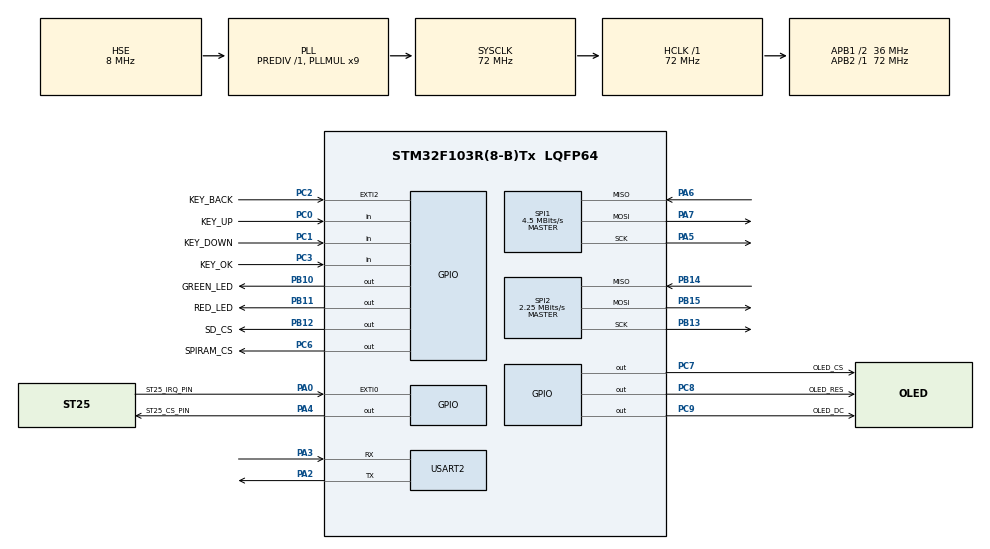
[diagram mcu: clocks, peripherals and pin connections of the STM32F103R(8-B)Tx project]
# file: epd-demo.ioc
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FATFS._CODE_PAGE=1252
FATFS._MAX_SS=512
FATFS._MIN_SS=512
FATFS._USE_LFN=1
Mcu.Family=STM32F1
Mcu.Name=STM32F103R(8-B)Tx
Mcu.Package=LQFP64
NVIC.EXTI0_IRQn=true\:0\:0\:false\:false\:true\:true\:true
NVIC.EXTI2_IRQn=true\:1\:0\:true\:false\:true\:true\:true
NVIC.PriorityGroup=NVIC_PRIORITYGROUP_4
NVIC.TIM3_IRQn=true\:0\:0\:false\:false\:true\:true\:true
PA0-WKUP.GPIO_Label=ST25_IRQ_PIN
PA0-WKUP.Signal=GPXTI0
PA13.Mode=Serial_Wire
PA13.Signal=SYS_JTMS-SWDIO
PA14.Mode=Serial_Wire
PA14.Signal=SYS_JTCK-SWCLK
PA2.Mode=Asynchronous
PA2.Signal=USART2_TX
PA3.Mode=Asynchronous
PA3.Signal=USART2_RX
PA4.GPIO_Label=ST25_CS_PIN
PA4.GPIO_PuPd=GPIO_PULLUP
PA4.GPIO_Speed=GPIO_SPEED_FREQ_HIGH
PA4.Signal=GPIO_Output
PA5.Mode=Full_Duplex_Master
PA5.Signal=SPI1_SCK
PA6.Mode=Full_Duplex_Master
PA6.Signal=SPI1_MISO
PA7.Mode=Full_Duplex_Master
PA7.Signal=SPI1_MOSI
PB10.GPIO_Label=GREEN_LED
PB10.GPIO_PuPd=GPIO_PULLDOWN
PB10.PinState=GPIO_PIN_RESET
PB10.Signal=GPIO_Output
PB11.GPIO_Label=RED_LED
PB11.GPIO_PuPd=GPIO_PULLDOWN
PB11.Signal=GPIO_Output
PB12.GPIO_Label=SD_CS
PB12.GPIO_PuPd=GPIO_PULLUP
PB12.GPIO_Speed=GPIO_SPEED_FREQ_HIGH
PB12.PinState=GPIO_PIN_SET
PB12.Signal=GPIO_Output
PB13.Mode=Full_Duplex_Master
PB13.Signal=SPI2_SCK
PB14.Mode=Full_Duplex_Master
PB14.Signal=SPI2_MISO
PB15.Mode=Full_Duplex_Master
PB15.Signal=SPI2_MOSI
PC0.GPIO_Label=KEY_UP
PC0.GPIO_PuPd=GPIO_PULLUP
PC0.Signal=GPIO_Input
PC1.GPIO_Label=KEY_DOWN
PC1.GPIO_PuPd=GPIO_PULLUP
PC1.Signal=GPIO_Input
PC2.GPIO_Label=KEY_BACK
PC2.GPIO_ModeDefaultEXTI=GPIO_MODE_IT_FALLING
PC2.GPIO_PuPd=GPIO_PULLUP
PC2.Signal=GPXTI2
PC3.GPIO_Label=KEY_OK
PC3.GPIO_PuPd=GPIO_PULLUP
PC3.Signal=GPIO_Input
PC6.GPIO_Label=SPIRAM_CS
PC6.GPIO_PuPd=GPIO_PULLUP
PC6.GPIO_Speed=GPIO_SPEED_FREQ_HIGH
PC6.PinState=GPIO_PIN_SET
PC6.Signal=GPIO_Output
PC7.GPIO_Label=OLED_CS
PC7.GPIO_PuPd=GPIO_PULLUP
PC7.GPIO_Speed=GPIO_SPEED_FREQ_HIGH
PC7.PinState=GPIO_PIN_SET
PC7.Signal=GPIO_Output
PC8.GPIO_Label=OLED_RES
PC8.GPIO_PuPd=GPIO_PULLUP
PC8.GPIO_Speed=GPIO_SPEED_FREQ_LOW
PC8.PinState=GPIO_PIN_RESET
PC8.Signal=GPIO_Output
PC9.GPIO_Label=OLED_DC
PC9.GPIO_Speed=GPIO_SPEED_FREQ_HIGH
PC9.PinState=GPIO_PIN_RESET
PC9.Signal=GPIO_Output
PD0-OSC_IN.Mode=HSE-External-Oscillator
PD0-OSC_IN.Signal=RCC_OSC_IN
PD1-OSC_OUT.Mode=HSE-External-Oscillator
PD1-OSC_OUT.Signal=RCC_OSC_OUT
ProjectManager.HeapSize=0x400
ProjectManager.StackSize=0x800
ProjectManager.TargetToolchain=MDK-ARM V5
RCC.AHBFreq_Value=72000000
RCC.APB1CLKDivider=RCC_HCLK_DIV2
RCC.APB1Freq_Value=36000000
RCC.APB1TimFreq_Value=72000000
RCC.APB2Freq_Value=72000000
RCC.APB2TimFreq_Value=72000000
RCC.HCLKFreq_Value=72000000
RCC.PLLMUL=RCC_PLL_MUL9
RCC.PLLSourceVirtual=RCC_PLLSOURCE_HSE
RCC.SYSCLKFreq_VALUE=72000000
RCC.SYSCLKSource=RCC_SYSCLKSOURCE_PLLCLK
RCC.USBFreq_Value=72000000
SPI1.BaudRatePrescaler=SPI_BAUDRATEPRESCALER_16
SPI1.CLKPhase=SPI_PHASE_2EDGE
SPI1.CalculateBaudRate=4.5 MBits/s
SPI1.Direction=SPI_DIRECTION_2LINES
SPI1.Mode=SPI_MODE_MASTER
SPI1.VirtualType=VM_MASTER
SPI2.BaudRatePrescaler=SPI_BAUDRATEPRESCALER_16
SPI2.CalculateBaudRate=2.25 MBits/s
SPI2.Direction=SPI_DIRECTION_2LINES
SPI2.Mode=SPI_MODE_MASTER
SPI2.VirtualType=VM_MASTER
TIM3.AutoReloadPreload=TIM_AUTORELOAD_PRELOAD_ENABLE
TIM3.Period=3999
TIM3.Prescaler=7199
USART2.VirtualMode=VM_ASYNC
VP_FATFS_VS_Generic.Mode=User_defined
VP_TIM3_VS_ClockSourceINT.Mode=Internal
board=epd1in54

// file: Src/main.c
/* USER CODE BEGIN Header */
/**
  ******************************************************************************
  * @file           : main.c
  * @brief          : Main program body
  ******************************************************************************
  * @attention
  *
  * <h2><center>&copy; Copyright (c) 2021 STMicroelectronics.
  * All rights reserved.</center></h2>
  *
  * This software component is licensed by ST under Ultimate Liberty license
  * SLA0044, the "License"; You may not use this file except in compliance with
  * the License. You may obtain a copy of the License at:
  *                             www.st.com/SLA0044
  *
  ******************************************************************************
  */
/* USER CODE END Header */
#include "main.h"
#include "fatfs.h"
#include "spi.h"
#include "tim.h"
#include "usart.h"
#include "gpio.h"

/* USER CODE BEGIN Includes */
#include "stdio.h"
#include "demo.h"
#include "platform.h"
#include "logger.h"
#include "st_errno.h"
#include "rfal_nfc.h"
#include "rfal_analogConfig.h"
/* USER CODE END Includes */

/* USER CODE BEGIN PTD */
uint8_t globalCommProtectCnt = 0;
/* USER CODE END PTD */

/* USER CODE BEGIN PV */
uint8_t nfcbuf[5000] = { /* 0X00,0X01,0XC8,0X00,0XC8,0X00, */
0XFF,0XFF,0XFF,0XFF,0XFF,0XFF,0XFF,0XFF,0XFF,0XFF,0XFF,0XFF,0XF0,0X1F,0XFF,0XFF,
0XFF,0XFF,0XFF,0XFF,0XFF,0XFF,0XFF,0XFF,0XFF,0XFF,0XFF,0XFF,0XFF,0XFF,0XFF,0XFF,
0XFF,0XFF,0XFF,0XFF,0XE0,0X40,0X0F,0XFF,0XFF,0XFF,0XFF,0XFF,0XFF,0XFF,0XFF,0XFF,
0XFF,0XFF,0XFF,0XFF,0XFF,0XFF,0XFF,0XFF,0XFF,0X03,0X00,0XFF,0XFF,0XC0,0X03,0X80,
0X1F,0XFF,0XFF,0XFF,0XFF,0XFF,0XFF,0XFF,0XFF,0XFF,0XFF,0XFF,0XFF,0XFF,0XFF,0XFF,
0XFF,0XE0,0X00,0X00,0X63,0XF8,0X07,0X1F,0XE0,0X07,0XFF,0XFF,0XFF,0XFF,0XFF,0XFF,
0XFF,0XFF,0XFF,0XFF,0XFF,0XFF,0XFF,0XFF,0XFF,0XFF,0XC0,0X38,0X3E,0X01,0XF0,0X1F,
0X9F,0XE7,0XC0,0X3F,0XFF,0XFF,0XFF,0XFF,0XFF,0XFF,0XFF,0XFF,0XFF,0XFF,0XFF,0XFF,
0XFF,0XFF,0XFF,0X8C,0XFC,0XFF,0X00,0XF0,0X9F,0X9F,0XE7,0XE0,0X00,0X3F,0XFF,0XFF,
0XFF,0XFF,0XFF,0XFF,0XFF,0XFF,0XFF,0XFF,0XFF,0XFF,0XFF,0XFF,0X9C,0XFC,0XFF,0X3C,
0X61,0X8F,0X9F,0XE7,0XE0,0X00,0X03,0XFF,0XFF,0XFF,0XFF,0XFF,0XFF,0XFF,0XFF,0XFF,
0XFF,0XFF,0XFF,0XFF,0XFF,0X9C,0XFC,0X7F,0X3C,0X01,0XDF,0XDF,0XF7,0XC7,0XF0,0X00,
0X3F,0XFF,0XFF,0XFF,0XFF,0XFF,0XFF,0XFF,0XFF,0XFF,0XFF,0XFF,0XFF,0XFF,0X9E,0XFF,
0X7F,0X3E,0X01,0XFF,0XFF,0XFF,0XC7,0XF0,0X00,0X03,0XFF,0XFF,0XFF,0XFF,0XFF,0XFF,
0XFF,0XFF,0XFF,0XFF,0XFF,0XFF,0XFF,0X9F,0XFF,0XFF,0XFC,0X30,0XFF,0XFF,0XFF,0XC7,
0XF0,0X1F,0X00,0XFF,0XFF,0XFF,0XFF,0XFF,0XFF,0XFF,0XFF,0XFF,0XFF,0XFF,0XFF,0XFF,
0X87,0XFF,0XFF,0XF8,0X78,0X7F,0XFF,0XFF,0X87,0XF0,0X0F,0XE0,0X1F,0XFF,0XFF,0XFF,
0XFF,0XFF,0XFF,0XFF,0XFF,0XFF,0XFF,0XFF,0XFF,0X83,0XFF,0XFF,0XF0,0XF8,0X3F,0XFF,
0XFF,0X8F,0XF0,0X0F,0XE0,0X07,0XFF,0XFF,0XFF,0XFF,0XFF,0XFF,0XFF,0XFF,0XFF,0XFF,
0XFF,0XFF,0X81,0XFF,0XFF,0XF0,0XFE,0X1F,0XFF,0XFE,0X0F,0XF8,0X0F,0XE0,0X81,0XFF,
0XFF,0XFF,0XFF,0XFF,0XFF,0XFF,0XFF,0XFF,0XFF,0XFF,0XFF,0XC1,0XFF,0XFF,0XE1,0XFF,
0X0F,0XFF,0XF8,0X0F,0XF8,0X07,0XC0,0XE0,0X7F,0XFF,0XFF,0XFF,0XFF,0XFF,0XFF,0XFF,
0XFF,0XFF,0XFF,0XFF,0XC1,0XFF,0XFF,0XC3,0XFF,0X07,0XFF,0XF0,0X0F,0XFC,0X00,0X80,
0XFC,0X1F,0XFF,0XFF,0XFF,0XFF,0XFF,0XFF,0XFF,0XFF,0XFF,0XFF,0XFF,0XC0,0X3F,0XFF,
0XC3,0XFF,0X83,0XFF,0XC0,0X0F,0XFC,0X00,0X01,0XFE,0X0F,0XFF,0XFF,0XFF,0XFF,0XFF,
0XFF,0XFF,0XFF,0XFF,0XFF,0XFF,0XC0,0X03,0XFF,0X83,0XFF,0XC3,0XFF,0X8F,0X8F,0XFE,
0X38,0X00,0XFE,0X03,0XFF,0XFF,0XFF,0XFF,0XFF,0XFF,0XFF,0XFF,0XFF,0XFF,0XFF,0XE0,
0X03,0XFF,0X87,0XFF,0XE1,0XFF,0XFF,0X8F,0XFE,0X3F,0XE0,0X3C,0X01,0XFF,0XFF,0XFF,
0XFF,0XFF,0XFF,0XFF,0XFF,0XFF,0XFF,0XFF,0XE1,0XFF,0XFF,0X87,0XFF,0XE0,0XFF,0XFF,
0X87,0XFE,0X3F,0XFC,0X08,0X18,0X7F,0XFF,0XFF,0XFF,0XFF,0XFF,0XFF,0XFF,0XFF,0XFF,
0XFF,0XC3,0XFF,0XFF,0X0F,0XFF,0XF0,0XFF,0XFF,0X87,0XF8,0X1F,0XFF,0X80,0X1C,0X3F,
0XFF,0XFF,0XFF,0XFF,0XFF,0XFF,0XFF,0XFF,0XFF,0XFF,0XC3,0XFF,0XFF,0X0F,0XFF,0XF8,
0X7F,0XFF,0X87,0XC0,0X1F,0XFF,0XE0,0X3E,0X1F,0XFF,0XFF,0XFF,0XFF,0XFF,0XFF,0XFF,
0XFF,0XFF,0XFF,0X87,0XFF,0XFF,0X0F,0XFF,0XF8,0X7F,0XFF,0XC3,0XC0,0X1F,0XFF,0XF8,
0X7F,0X8F,0XFF,0XFF,0XFF,0XFF,0XFF,0XFF,0XFF,0XFF,0XFF,0XFF,0X87,0XFF,0XFE,0X1F,
0XFF,0XFC,0X3F,0XFF,0XC3,0XFC,0X8F,0XFF,0XFC,0X1F,0X87,0XFF,0XFF,0XFF,0XFF,0XFF,
0XFF,0XFF,0XFF,0XFF,0XFF,0X0F,0XFF,0XFE,0X1F,0XFF,0XFC,0X3F,0XFF,0X81,0XFF,0X8F,
0XFF,0XFF,0X0F,0X03,0XFF,0XFF,0XFF,0XFF,0XFF,0XFF,0XFF,0XFF,0XFF,0XFF,0X0F,0XFF,
0XFE,0X1F,0XFF,0XFE,0X3F,0XFE,0X01,0XFF,0XCF,0XFF,0XFF,0X84,0X01,0XFF,0XFF,0XFF,
0XFF,0XFF,0XFF,0XFF,0XFF,0XFF,0XFE,0X00,0XFF,0XFC,0X1F,0XFF,0XFE,0X1F,0XFC,0X00,
0XFF,0XCF,0XFF,0XFF,0XC0,0X01,0XFF,0XFF,0XFF,0XFF,0XFF,0XFF,0XFF,0XFF,0XFF,0XFE,
0X00,0X0F,0XFC,0X3F,0XFF,0XFE,0X1F,0XF8,0X00,0XFF,0X87,0XFF,0XFF,0XE0,0X08,0XFF,
0XFF,0XFF,0XFF,0XFF,0XFF,0XFF,0XFF,0XFF,0XFE,0X00,0X03,0XFC,0X3F,0XFF,0XFE,0X1F,
0XE0,0X00,0X7E,0X07,0XFF,0XFF,0XF0,0X0C,0X7F,0XFF,0XFF,0XFF,0XFF,0XFF,0XFF,0XFF,
0XFF,0XFC,0X00,0X00,0XFC,0X3F,0XFF,0XFF,0X1F,0XE1,0XF8,0X70,0X07,0XFF,0XFF,0XF8,
0X1E,0X7F,0XFF,0XFF,0XFF,0XFF,0XFF,0XFF,0XFF,0XFF,0XFC,0X3F,0XFC,0XFC,0X7F,0XFF,
0XFF,0X1F,0XFF,0XF8,0X30,0X07,0XFF,0XFF,0XFC,0X7E,0X3F,0XFF,0XFF,0XFF,0XFF,0XFF,
0XFF,0XFF,0XFF,0XFC,0X3F,0XFF,0XFC,0X7F,0XFF,0XFF,0X0F,0XFF,0XFC,0X3F,0XE7,0XFF,
0XFF,0XFE,0X3C,0X1F,0XFF,0XFF,0XFF,0XFF,0XFF,0XFF,0XFF,0XFF,0XF8,0X7F,0XFF,0XF8,
0X7F,0XFF,0XFF,0X0F,0XFF,0XFC,0X3F,0XE7,0XFF,0XFF,0XFE,0X38,0X1F,0XFF,0XFF,0XFF,
0XFF,0XFF,0XFF,0XFF,0XFF,0XF8,0X7F,0XFF,0XF8,0X7F,0XFF,0XFF,0X0F,0XFF,0XFC,0X1F,
0XE7,0XFF,0XFF,0XFF,0X00,0X0F,0XFF,0XFF,0XFF,0XFF,0XFF,0XFF,0XFF,0XFF,0XF8,0X5F,
0XFF,0XF8,0X7F,0XFF,0XFF,0X0F,0XFF,0XFE,0X1F,0XE7,0XFF,0XFF,0XFF,0X80,0X0F,0XFF,
0XFF,0XFF,0XFF,0XFF,0XFF,0XFF,0XFF,0XF8,0X01,0XFF,0XF8,0X7F,0XFF,0XFF,0X8F,0XFF,
0XF8,0X0F,0XE7,0XFF,0XFF,0XFF,0X80,0X07,0XFF,0XFF,0XFF,0XFF,0XFF,0XFF,0XFF,0XFF,
0XF8,0X00,0X7F,0XF8,0XFF,0XFF,0XFF,0X8F,0XFF,0XC0,0X0F,0XC7,0XFF,0XFF,0XFF,0X80,
0X07,0XFF,0XFF,0XFF,0XFF,0XFF,0XFF,0XFF,0XFF,0XF0,0X00,0X1F,0XF8,0XFF,0XFF,0XFF,
0X8F,0XFF,0X80,0X0F,0X07,0XFF,0XFF,0XFF,0XC0,0X27,0XFF,0XFF,0XFF,0XFF,0XFF,0XFF,
0XFF,0XFF,0XF0,0X00,0X07,0XF8,0XFF,0XFF,0XFF,0X8F,0XFE,0X00,0X00,0X07,0XFF,0XFF,
0XFF,0XC0,0X63,0XFF,0XFF,0XFF,0XFF,0XFF,0XFF,0XFF,0XFF,0XF0,0X00,0X03,0XF8,0XFF,
0XFF,0XFF,0X87,0XFC,0X00,0X04,0X07,0XFF,0XFF,0XFF,0XE7,0XE3,0XFF,0XFF,0XFF,0XFF,
0XFF,0XFF,0XFF,0XFF,0XF1,0XFF,0XF1,0XF8,0XFF,0XFF,0XFF,0X87,0XF0,0X18,0X07,0X47,
0XFF,0XFF,0XFF,0XE7,0XF3,0XFF,0XFF,0XFF,0XFF,0XFF,0XFF,0XFF,0XFF,0XF1,0XFF,0XFF,
0XF8,0XFF,0XFF,0XFF,0XC7,0XF3,0XFF,0X87,0XC7,0XFF,0XFF,0XFF,0XE3,0XF3,0XFF,0XFF,
0XFF,0XFF,0XFF,0XFF,0XFF,0XFF,0XF1,0XFF,0XFF,0XF9,0XFF,0XFF,0XFF,0XC7,0XFF,0XFF,
0X87,0XCF,0XFF,0XFF,0XFF,0XF3,0XC1,0XFF,0XFF,0XFF,0XFF,0XFF,0XFF,0XFF,0XFF,0XF1,
0XFF,0XFF,0XF9,0XFF,0XFF,0XFF,0XC7,0XFF,0XFF,0X87,0X8F,0XFF,0XFF,0XFF,0XF0,0X01,
0XFF,0XFF,0XFF,0XFF,0XFF,0XFF,0XFF,0XFF,0XF1,0XFF,0XFF,0XF9,0XFF,0XFF,0XFF,0XE7,
0XFF,0XFF,0X87,0X8F,0XFF,0XFF,0XFF,0XF8,0X01,0XFF,0XFF,0XFF,0XFF,0XFF,0XFF,0XFF,
0XFF,0XF1,0XFF,0XFF,0XF9,0XFF,0XFF,0XFF,0XFF,0XFF,0XFF,0XC7,0X9F,0XFF,0XFF,0XFF,
0XF8,0X01,0XFF,0XFF,0XFF,0XFF,0XFF,0XFF,0XFF,0XFF,0XF0,0X3F,0XFF,0XF9,0XFF,0XFF,
0XFF,0XFF,0XFF,0XF8,0X07,0X1F,0XFF,0XFF,0XFF,0XFC,0X01,0XFF,0XFF,0XFF,0XFF,0XFF,
0XFF,0XFF,0XFF,0XF0,0X03,0XFF,0XFF,0XFF,0XFF,0XFF,0XFF,0XFF,0XC0,0X07,0X1F,0XFF,
0XFF,0XFF,0XFC,0X59,0XFF,0XFF,0XFF,0XFF,0XFF,0XFF,0XFF,0XFF,0XF0,0X00,0X7F,0XFF,
0XFF,0XFF,0XFF,0XFF,0XFF,0X00,0X03,0X3F,0XFF,0XFF,0XFF,0XFE,0X79,0XFF,0XFF,0XFF,
0XFF,0XFF,0XFF,0XFF,0XFF,0XF0,0X00,0X1F,0XFF,0XFF,0XFF,0XFF,0XFF,0XFC,0X00,0X06,
0X3F,0XFF,0XFF,0XFF,0XFE,0X39,0XFF,0XFF,0XFF,0XFF,0XFF,0XFF,0XFF,0XFF,0XF0,0X00,
0X0F,0XFF,0XFF,0XFF,0XFF,0XFF,0XF0,0X00,0X06,0X7F,0XFF,0XFF,0XFF,0XFF,0X01,0XFF,
0XFF,0XFF,0XFF,0XFF,0XFF,0XFF,0XFF,0XF0,0X00,0X03,0XFF,0XFF,0XFF,0XFF,0XFF,0XF3,
0XF8,0X04,0X7F,0XFF,0XFF,0XFF,0XFF,0X83,0XFF,0XFF,0XFF,0XFF,0XFF,0XFF,0XFF,0XFF,
0XF1,0XFF,0XC1,0XFF,0XFF,0XFF,0XFF,0XFF,0XFF,0XFF,0X84,0XFF,0XFF,0XFF,0XFF,0XFF,
0XFF,0XFF,0XFF,0XFF,0XFF,0XFF,0XFF,0XFF,0XFF,0XF1,0XFF,0XFF,0XFF,0XFF,0XFF,0XFF,
0XFF,0XFF,0XFF,0XC0,0XFF,0XFF,0XFF,0XFF,0XFF,0XFF,0XFF,0XFF,0XFF,0XFF,0XFF,0XFF,
0XFF,0XFF,0XF1,0XFF,0XFF,0XFF,0XFF,0XFF,0XFF,0XFF,0XFF,0XFF,0XC1,0XFF,0XFF,0XFF,
0XFF,0XFF,0XFF,0XFF,0XFF,0XFF,0XFF,0XFF,0XFF,0XFF,0XFF,0XD9,0XFF,0XFF,0XFF,0XFF,
0XFF,0XFF,0XFF,0XFF,0XFF,0XC1,0XFF,0XFF,0XFF,0XFF,0XFF,0XFF,0XFF,0XFF,0XFF,0XFF,
0XFF,0XFF,0XFF,0XFF,0XC9,0XFF,0XFF,0XFF,0XFF,0XFF,0XFF,0XFF,0XFF,0XFF,0XC3,0XFF,
0XFF,0XFF,0XFF,0XFF,0XFF,0XFF,0XFF,0XFF,0XFF,0XFF,0XFF,0XFF,0XFF,0XC1,0XFF,0XFF,
0XFF,0XFF,0XFF,0XFF,0XFF,0XFF,0XFF,0XC7,0XFF,0XFF,0XFF,0XFF,0XFF,0XFF,0XFF,0XFF,
0XFF,0XFF,0XFF,0XFF,0XFF,0XFF,0XC0,0XFF,0XFF,0XFF,0XFF,0XFF,0XFF,0XFF,0XFF,0XFF,
0XCE,0XFF,0XFF,0XFF,0XFF,0XFF,0XFF,0XFF,0XFF,0XFF,0XFF,0XFF,0XFF,0XFF,0XFF,0XE0,
0XFF,0XFF,0XFF,0XFF,0XFF,0XFF,0XFF,0XFF,0XFF,0X80,0XFF,0XFF,0XFF,0XFF,0XFF,0XFF,
0XFF,0XFF,0XFF,0XFF,0XFF,0XFF,0XFF,0XFF,0XE0,0XFF,0XFF,0XFF,0XFF,0XFF,0XFF,0XFF,
0XFF,0XFF,0X01,0XFF,0XFF,0XFF,0XFF,0XFF,0XFF,0XFF,0XFF,0XFF,0XFF,0XFF,0XFF,0XFF,
0XFF,0XE2,0XFF,0XFF,0XFF,0XFF,0XFF,0XFF,0XFE,0X00,0X00,0X03,0XFF,0XFF,0XFF,0XFF,
0XFF,0XFF,0XFF,0XFF,0XFF,0XFF,0XFF,0XFF,0XFF,0XFF,0XF3,0XFF,0X07,0XFF,0XFF,0XFF,
0XFF,0XE0,0X00,0X00,0X07,0XFF,0XFF,0XFF,0XFF,0XFF,0XFF,0XFF,0XFF,0XFF,0XFF,0XFF,
0XFF,0XFF,0XFF,0XF1,0XE0,0X00,0X1F,0XFF,0XFF,0XFF,0X80,0X00,0X00,0X07,0XFF,0XFF,
0XFF,0XFF,0XFF,0XFF,0XFF,0XFF,0XFF,0XFF,0XFF,0XFF,0XFF,0XFF,0XF8,0X80,0X00,0X03,
0XFF,0XFF,0XFE,0X00,0X00,0X00,0X0F,0XFF,0XFF,0XFF,0XFF,0XFF,0XFF,0XFF,0XFF,0XFF,
0XFF,0XFF,0XFF,0XFF,0XFF,0XC0,0X00,0X00,0X00,0X7F,0XFF,0XF8,0X00,0X00,0X00,0X1F,
0XFF,0XFF,0XFF,0XFF,0XFF,0XFF,0XFF,0XFF,0XFF,0XFF,0XFF,0XFF,0XFF,0XFF,0XE0,0X00,
0X00,0X00,0X1F,0XFF,0XF0,0XFF,0XF0,0X00,0X1F,0XFF,0XFF,0XFF,0XFF,0XFF,0XFF,0XFF,
0XFF,0XFF,0XFF,0XFF,0XFF,0XFF,0XFF,0XF0,0X00,0X00,0X00,0X07,0XFF,0XFF,0XFF,0XFF,
0X00,0X01,0XFF,0XFF,0XFF,0XFF,0XFF,0XFF,0XFF,0XFF,0XFF,0XFF,0XFF,0XFF,0XFF,0XFF,
0XF8,0X00,0X00,0X00,0X07,0XFF,0XFF,0XFF,0XFF,0XC0,0X03,0XFF,0XFF,0XFF,0XFF,0XFF,
0XFF,0XFF,0XFF,0XFF,0XFF,0XFF,0XFF,0XFF,0XFF,0XF8,0X00,0X07,0XFF,0XFF,0XFF,0XFF,
0XFF,0XFF,0XF0,0X07,0XFF,0XFF,0XFF,0XFF,0XFF,0XFF,0XFF,0XFF,0XFF,0XFF,0XFF,0XFF,
0XFF,0XFF,0XFC,0X00,0X3F,0XFF,0XFF,0XFF,0XFF,0XFF,0XFF,0XF8,0X0F,0XFF,0XFF,0XFF,
0XFF,0XFF,0XFF,0XFF,0XFF,0XFF,0XFF,0XFF,0XFF,0XFF,0XFF,0XFE,0X01,0XFF,0XFF,0XFF,
0XFF,0XFF,0XFF,0XFF,0XFE,0X1F,0XFF,0XFF,0XFF,0XFF,0XFF,0XFF,0XFF,0XFF,0XFF,0XFF,
0XFF,0XFF,0XFF,0XFF,0XFE,0X0F,0XFF,0XFF,0XFF,0XFF,0XFF,0XFF,0XFF,0XFE,0X3F,0XFF,
0XFF,0XFF,0XFF,0XFF,0XFF,0XFF,0XFF,0XFF,0XFF,0XFF,0XFF,0XFF,0XFF,0XFF,0X1F,0XFF,
0XFF,0XFF,0XFF,0XFF,0XFF,0XFF,0XFC,0X7F,0XFF,0XFF,0XFF,0XFF,0XFF,0XFF,0XFF,0XFF,
0XFF,0XFF,0XFF,0XFF,0XFF,0XFF,0XFF,0X1F,0XFF,0XFF,0XFF,0XFF,0XFF,0XFF,0X00,0XFC,
0XFF,0XFF,0XFF,0XFF,0XFF,0XFF,0XFF,0XFF,0XFF,0XFF,0XFF,0XFF,0XFF,0XFF,0XFF,0XFF,
0X1F,0XFF,0XFF,0XFF,0XFF,0XFF,0XE0,0X00,0X00,0XFF,0XFF,0XFF,0XFF,0XFF,0XFF,0XFF,
0XFF,0XFF,0XFF,0XFF,0XFF,0XFF,0XFF,0XFF,0XF0,0X1F,0XFF,0XFF,0XFF,0XFF,0XFF,0XC0,
0X00,0X01,0XFF,0XFF,0XFF,0XFF,0XFF,0XFF,0XFF,0XFF,0XFF,0XFF,0XFF,0XFF,0XFF,0XFF,
0XFF,0XF0,0X0F,0XFF,0XFF,0XFF,0XFF,0XFF,0XC0,0X00,0X01,0XFF,0XFF,0XFF,0XFF,0XFF,
0XFF,0XFF,0XFF,0XFF,0XFF,0XFF,0XFF,0XFF,0XFF,0XFF,0XF8,0X0F,0XF8,0X00,0X1F,0XFF,
0XFF,0XFF,0X80,0X03,0XFF,0XFF,0XFF,0XFF,0XFF,0XFF,0XFF,0XFF,0XFF,0XFF,0XFF,0XFF,
0XFF,0XFF,0XFF,0XFE,0X1F,0X80,0X00,0X3F,0XFF,0XFF,0XFF,0XF0,0X03,0XFF,0XFF,0XFF,
0XFF,0XFF,0XFF,0XFF,0XFF,0XFF,0XFF,0XFF,0XFF,0XFF,0XFF,0XFF,0XFF,0X0E,0X00,0X07,
0XFF,0XFF,0XFF,0XFF,0XFE,0X07,0XFF,0XFF,0XFF,0XFF,0XFF,0XFF,0XFF,0XFF,0XFF,0XFF,
0XFF,0XFF,0XFF,0XFF,0XFF,0XFF,0X80,0X00,0X1F,0XFF,0XFF,0XFF,0XFF,0XFF,0X07,0XFF,
0XFF,0XFF,0XFF,0XFF,0XFF,0XFF,0XFF,0XFF,0XFF,0XFF,0XFF,0XFF,0XFF,0XFF,0XFF,0XE0,
0X00,0X7F,0XFF,0XFF,0XFF,0XFF,0XFF,0XC7,0XFF,0XFF,0XFF,0XFF,0XFF,0XFF,0XFF,0XFF,
0XFF,0XFF,0XFF,0XFF,0XFF,0XFF,0XFF,0XFF,0XE0,0X01,0XFF,0XFF,0XFF,0XFF,0XFF,0XFF,
0XC7,0XFF,0XFF,0XFF,0XFF,0XFF,0XFF,0XFF,0XFF,0XFF,0XFF,0XFF,0XFF,0XFF,0XFF,0XFF,
0XFF,0XF0,0X03,0XFF,0XFF,0XFF,0XFF,0XFF,0XFF,0XCF,0XFF,0XFF,0XFF,0XFF,0XFF,0XFF,
0XFF,0XFF,0XFF,0XFF,0XFF,0XFF,0XFF,0XFF,0XFF,0XFF,0XF8,0X07,0XFF,0XFF,0XFF,0X00,
0X00,0X01,0XCF,0XFF,0XFF,0XFF,0XFF,0XFF,0XFF,0XFF,0XFF,0XFF,0XFF,0XFF,0XFF,0XFF,
0XFF,0XFF,0XFF,0XF8,0X0F,0XFF,0XFF,0X80,0X00,0X00,0X00,0X0F,0XFF,0XFF,0XFF,0XFF,
0XFF,0XFF,0XFF,0XFF,0XFF,0XFF,0XFF,0XFF,0XFF,0XFF,0XFF,0XFF,0XFC,0X1F,0XFF,0XF8,
0X00,0X00,0X00,0X00,0X00,0XFF,0XFF,0XFF,0XFF,0XFF,0XFF,0XFF,0XFF,0XFF,0XFF,0XFF,
0XFF,0XFF,0XFF,0XFF,0XFF,0XFE,0X3F,0XFF,0XC0,0X01,0XFF,0XFF,0XFF,0X00,0X0F,0XFF,
0XFF,0XFF,0XFF,0XFF,0XFF,0XFF,0XFF,0XFF,0XFF,0XFF,0XFF,0XFF,0XFF,0XFF,0XFE,0X3F,
0XFE,0X00,0X7F,0XFF,0XFF,0XFF,0XF8,0X01,0XFF,0XFF,0XFF,0XFF,0XFF,0XFF,0XFF,0XFF,
0XFF,0XFF,0XFF,0XFF,0XFF,0XFF,0XFF,0XFE,0X3F,0XF0,0X07,0XFF,0XFF,0XFF,0XFF,0XFF,
0XC0,0X3F,0XFF,0XFF,0XFF,0XFF,0XFF,0XFF,0XFF,0XFF,0XFF,0XFF,0XFF,0XFF,0XFF,0XFF,
0XFF,0X3F,0XC0,0X7F,0XFF,0XFF,0XFF,0XFF,0XFF,0XF8,0X07,0XFF,0XFF,0XFF,0XFF,0XFF,
0XFF,0XFF,0XFF,0XFF,0XFF,0XFF,0XFF,0XFF,0XFF,0XFF,0X1F,0X01,0XFF,0XFF,0XFF,0XFF,
0XFF,0XFF,0XFF,0X01,0XFF,0XFF,0XFF,0XFF,0XFF,0XFF,0XFF,0XFF,0XFF,0XFF,0XFF,0XFF,
0XFF,0XFF,0XFF,0X1C,0X0F,0XFF,0XFF,0XFF,0XFF,0XFF,0XFF,0XFF,0XE0,0X7F,0XFF,0XFF,
0XFF,0XFF,0XFF,0XFF,0XFF,0XFF,0XFF,0XFF,0XFF,0XFF,0XFF,0XFF,0X90,0X3F,0XFF,0XFF,
0XFF,0XFF,0XFF,0XFF,0XFF,0XF8,0X1F,0XFF,0XFF,0XFF,0XFF,0XFF,0XFF,0XFF,0XFF,0XFF,
0XFF,0XFF,0XFF,0XFF,0XFF,0X80,0XFF,0XFF,0XFF,0XFF,0XFF,0XFF,0XFF,0XFF,0XF8,0X1F,
0XFF,0XFF,0XFF,0XFF,0XFF,0XFF,0XFF,0XFF,0XFF,0XFF,0XFF,0XFF,0XFF,0XFF,0X83,0XFF,
0XFF,0XFF,0XFF,0XFF,0XFF,0XFF,0XFF,0XF1,0XFF,0XFF,0XFF,0XFF,0XFF,0XFF,0XFF,0XFF,
0XFF,0XFF,0XFF,0XFF,0XFF,0XFF,0XFF,0X0F,0XFF,0XFF,0XFF,0XFF,0XFF,0XFF,0XFF,0XFF,
0XE3,0XFF,0XFF,0XFF,0XFF,0XFF,0XFF,0XFF,0XFF,0XFF,0XFF,0XFF,0XFF,0XFF,0XFF,0XFC,
0X1F,0XFF,0XFF,0XE1,0XFF,0XFF,0XFF,0XFF,0XFF,0XC0,0X1F,0XFF,0XFF,0XFF,0XFF,0XFF,
0XFF,0XFF,0XFF,0XFF,0XFF,0XFF,0XFF,0XFF,0XF8,0X7F,0XFF,0XFF,0X00,0X7F,0XFF,0XFF,
0XFF,0XFF,0XC0,0X03,0XFF,0XFF,0XFF,0XFF,0XFF,0XFF,0XFF,0XFF,0XFF,0XFF,0XFF,0XFF,
0XFF,0XF0,0XFF,0XFF,0XFE,0X00,0X3F,0XFF,0XFF,0XFF,0XFF,0XFF,0X00,0XFF,0XFF,0XFF,
0XFF,0XFF,0XFF,0XFF,0XFF,0XFF,0XFF,0XFF,0XFF,0XFF,0XE3,0XFF,0XFF,0XFC,0X00,0X1F,
0XFF,0XFF,0XFF,0XFF,0XFF,0XF8,0X7F,0XFF,0XFF,0XFF,0XFF,0XFF,0XFF,0XFF,0XFF,0XFF,
0XFF,0XFF,0XFF,0X87,0XFF,0XFF,0XF8,0X0F,0X8F,0XFF,0XFF,0XFF,0XFF,0XFF,0XE0,0X3F,
0XFF,0XFF,0XFF,0XFF,0XFF,0XFF,0XFF,0XFF,0XFF,0XFF,0XFF,0XFF,0X0F,0XFF,0XFF,0XF0,
0X7F,0XE7,0XFF,0XFF,0XFF,0XFF,0XFF,0XC1,0XFF,0XFF,0XFF,0XFF,0XFF,0XFF,0XFF,0XFF,
0XFF,0XFF,0XFF,0XFF,0XFE,0X1F,0XFF,0XFF,0XF0,0XFF,0XF7,0XFF,0XFF,0XFF,0XFF,0XFF,
0X87,0XFF,0XFF,0XFF,0XFF,0XFF,0XFF,0XFF,0XFF,0XFF,0XFF,0XFF,0XFF,0XFC,0X3F,0XFF,
0XFF,0XF1,0XFF,0XFF,0XFF,0XFF,0XFF,0XFF,0XFF,0X01,0XFF,0XFF,0XFF,0XFF,0XFF,0XFF,
0XFF,0XFF,0XFF,0XFF,0XFF,0XFF,0XF8,0X7F,0XFF,0XFF,0XF3,0XFF,0XFF,0XFF,0XFF,0XFF,
0XFF,0XFE,0X00,0X7F,0XFF,0XFF,0XFF,0XFF,0XFF,0XFF,0XFF,0XFF,0XFF,0XFF,0XFF,0XF8,
0XFF,0XFF,0XFF,0XF3,0XFF,0XFF,0XFF,0XFF,0XFF,0XFF,0XFF,0XC0,0X1F,0XFF,0XFF,0XFF,
0XFF,0XFF,0XFF,0XFF,0XFF,0XFF,0XFF,0XFF,0XF1,0XFF,0XFF,0XFF,0XF3,0XFF,0XFF,0XFF,
0XFF,0XFF,0XFF,0XFF,0XC0,0X0F,0XFF,0XFF,0XFF,0XFF,0XFF,0XFF,0XFF,0XFF,0XFF,0XFF,
0XFF,0XE3,0XFF,0XFF,0XFF,0XF3,0XFF,0XFF,0XFF,0XFF,0XFF,0XFF,0XFF,0XC0,0X07,0XFF,
0XFF,0XFF,0XFF,0XFF,0XFF,0XFF,0XFF,0XFF,0XFF,0XFF,0XC7,0XFF,0XFF,0XFF,0XFB,0XFF,
0XFF,0XFF,0XFF,0XFF,0XFF,0XFF,0XC0,0X07,0XFF,0XFF,0XFF,0XFF,0XFF,0XFF,0XFF,0XFF,
0XFF,0XFF,0XFF,0X8F,0XFF,0XFF,0XFF,0XFF,0XFF,0XFF,0XFF,0XFF,0XFF,0XFF,0XFF,0XC0,
0X1F,0XFF,0XFF,0XFF,0XFF,0XFF,0XFF,0XFF,0XFF,0XFF,0XFF,0XFF,0X8F,0XFF,0XFF,0XFF,
0XFF,0XF0,0X0F,0XFF,0XFF,0XFF,0XFF,0XFF,0XC0,0X1F,0XFF,0XFF,0XFF,0XFF,0XFF,0XFF,
0XFF,0XFF,0XFF,0XFF,0XFF,0X1F,0XFF,0XFF,0XFF,0XFF,0XE0,0X07,0XFF,0XFF,0XFF,0XFF,
0XFF,0XC0,0X3F,0XFF,0XFF,0XFF,0XFF,0XFF,0XFF,0XFF,0XFF,0XFF,0XFF,0XFE,0X3F,0XFF,
0XFF,0XFF,0XFF,0XC0,0X03,0XFF,0XFF,0XFF,0XFF,0XFF,0XC0,0X3F,0XFF,0XFF,0XFF,0XFF,
0XFF,0XFF,0XFF,0XFF,0XFF,0XFF,0XFE,0X3F,0XFF,0XFF,0XFF,0XFF,0X80,0X01,0XFF,0XFF,
0XFF,0XFF,0XFF,0XC0,0X3F,0XFF,0XFF,0XFF,0XFF,0XFF,0XFF,0XFF,0XFF,0XFF,0XFF,0XFC,
0X1F,0XFF,0XFF,0XFF,0XFF,0X00,0X00,0XFF,0XFF,0XFF,0XFF,0XFF,0XC0,0X3F,0XFF,0XFF,
0XFF,0XFF,0XFF,0XFF,0XFF,0XFF,0XFF,0XFF,0XFF,0X0F,0XFF,0XFF,0XFF,0XFF,0X00,0X00,
0X7F,0XFF,0XFF,0XFF,0XFF,0XC0,0X3F,0XFF,0XFF,0XFF,0XFF,0XFF,0XFF,0XFF,0XFF,0XFF,
0XFF,0XFF,0XC7,0XFF,0XFF,0XFF,0XFF,0X00,0X00,0X3F,0XFF,0XFF,0XFF,0XF9,0XC0,0X3F,
0XFF,0XFF,0XFF,0XFF,0XFF,0XFF,0XFF,0XFF,0XFF,0XFF,0XFF,0XE7,0XFF,0XFF,0XFF,0XFE,
0X00,0X00,0X3F,0XFF,0XFF,0XFF,0XF9,0X81,0X3F,0XFF,0XFF,0XFF,0XFF,0XFF,0XFF,0XFF,
0XFF,0XFF,0XFF,0XFE,0X03,0XFF,0XFF,0XFF,0XFE,0X00,0X00,0X1F,0XFF,0XFF,0XFF,0XF3,
0X81,0X1F,0XFF,0XFF,0XFF,0XFF,0XFF,0XFF,0XFF,0XFF,0XFF,0XFF,0XF8,0X03,0XFF,0XFF,
0XFF,0XFE,0X00,0X00,0X1F,0XFF,0XFF,0XFF,0XE7,0X81,0X0F,0XFF,0XFF,0XFF,0XFF,0XFF,
0XFF,0XFF,0XFF,0XFF,0XFF,0XF0,0X03,0XFF,0XFF,0XFF,0XFE,0X00,0X00,0X0F,0XFF,0XFF,
0XFF,0XCF,0X83,0X07,0XFF,0XFF,0XFF,0XFF,0XFF,0XFF,0XFF,0XFF,0XFF,0XFF,0XE3,0XFF,
0XFF,0XFF,0XFF,0XFE,0X00,0X00,0X0F,0XFF,0XFF,0XFF,0X9F,0X87,0X03,0XFF,0XFF,0XFF,
0XFF,0XFF,0XFF,0XFF,0XFF,0XFF,0XFF,0XC1,0XFF,0XFF,0XFF,0XFF,0XFE,0X00,0X00,0X07,
0XFF,0XFF,0XFF,0X1F,0X03,0X13,0XFF,0XFF,0XFF,0XFF,0XFF,0XFF,0XFF,0XFF,0XFF,0XFF,
0X80,0X7F,0XFF,0XFF,0XFF,0XFE,0X00,0X00,0X07,0XFF,0XFF,0XFE,0X3F,0X03,0X11,0XFF,
0XFF,0XFF,0XFF,0XFF,0XFF,0XFF,0XFF,0XFF,0XFF,0X80,0X3F,0XFF,0XFF,0XFF,0XFE,0X00,
0X00,0X03,0XFF,0XFF,0XFC,0X7F,0X07,0X18,0XFF,0XFF,0XFF,0XFF,0XFF,0XFF,0XFF,0XFF,
0XFF,0XFF,0XFE,0X1F,0XFF,0XFF,0XFF,0XFE,0X00,0X00,0X03,0XFF,0XFF,0XF8,0XFE,0X0F,
0X1C,0X7F,0XFF,0XFF,0XFF,0XFF,0XFF,0XFF,0XFF,0XFF,0XFF,0XF8,0X07,0XFF,0XFF,0XFF,
0XFE,0X00,0X00,0X01,0XFF,0XFF,0XF1,0XFE,0X3F,0X1C,0X7F,0XFF,0XFF,0XFF,0XFF,0XFF,
0XFF,0XFF,0XFF,0XFF,0XF0,0X0F,0XFF,0XFF,0XFF,0XFE,0X00,0X00,0X01,0XFF,0XFF,0XE3,
0XFC,0X7F,0X1E,0X3F,0XFF,0XFF,0XFF,0XFF,0XFF,0XFF,0XFF,0XFF,0XFF,0XC0,0X0F,0XFF,
0XFF,0XFF,0XFF,0X00,0X00,0X00,0XFF,0XFF,0XC7,0XF8,0XFF,0X1F,0X1F,0XFF,0XFF,0XFF,
0XFF,0XFF,0XFF,0XFF,0XFF,0XFF,0X80,0X07,0XFF,0XFF,0XFF,0XFF,0X00,0X00,0X00,0X7F,
0XFF,0X9F,0XF1,0XFF,0X1F,0X1F,0XFF,0XFF,0XFF,0XFF,0XFF,0XFF,0XFF,0XFF,0XFF,0X80,
0X03,0XFF,0XFF,0XFF,0XFF,0X00,0X00,0X00,0X3F,0XFE,0X3F,0XC3,0XFF,0X1F,0X8F,0XFF,
0XFF,0XFF,0XFF,0XFF,0XFF,0XFF,0XFF,0XFF,0X00,0X01,0XFF,0XFF,0XFF,0XFF,0X00,0X00,
0X00,0X1F,0XFC,0X7F,0X8F,0XFF,0X1F,0X8F,0XFF,0XFF,0XFF,0XFF,0XFF,0XFF,0XFF,0XFF,
0XFE,0X00,0X00,0X1F,0XFF,0XFF,0XFF,0X00,0X00,0X00,0X00,0XF1,0XFE,0X3F,0XF9,0X1F,
0XC7,0XFF,0XFF,0XFF,0XFF,0XFF,0XFF,0XFF,0XFF,0XFE,0X00,0X00,0X07,0XFF,0XFF,0XFF,
0X00,0X00,0X00,0X00,0X23,0XF8,0X7F,0XE1,0X1F,0XE7,0XFF,0XFF,0XFF,0XFF,0XFF,0XFF,
0XFF,0XFF,0XFF,0XC0,0X00,0X23,0XFF,0XFF,0XFF,0X00,0X00,0X00,0X00,0X0F,0XE1,0XFF,
0XC3,0X1F,0XE3,0XFF,0XFF,0XFF,0XFF,0XFF,0XFF,0XFF,0XFF,0XFF,0XF8,0X00,0X10,0XFF,
0XFF,0XFF,0X00,0X00,0X00,0X3E,0X1F,0X87,0XFE,0X0F,0X1F,0XF3,0XFF,0XFF,0XFF,0XFF,
0XFF,0XFF,0XFF,0XFF,0XFF,0XFC,0X00,0X0C,0X1F,0XFF,0XFF,0X00,0X00,0X00,0XFC,0X7E,
0X1F,0XF8,0X3F,0X1F,0XF1,0XFF,0XFF,0XFF,0XFF,0XFF,0XFF,0XFF,0XFF,0XFF,0XFC,0X40,
0X07,0X07,0XFF,0XFF,0X00,0X00,0X01,0XFC,0XF0,0X7F,0XE0,0XFE,0X0F,0XF9,0XFF,0XFF,
0XFF,0XFF,0XFF,0XFF,0XFF,0XFF,0XFF,0XFC,0X70,0X01,0XC1,0XFF,0XFF,0X00,0X00,0X03,
0XFF,0XC1,0XFF,0X83,0XFE,0X0F,0XF8,0XFF,0XFF,0XFF,0XFF,0XFF,0XFF,0XFF,0XFF,0XFF,
0XFE,0X3E,0X00,0XF0,0X3F,0XFF,0X00,0X00,0X03,0XFC,0X07,0XFC,0X1F,0XFE,0X07,0XFC,
0XFF,0XFF,0XFF,0XFF,0XFF,0XFF,0XFF,0XFF,0XFF,0XFE,0X3F,0X80,0X7E,0X0F,0XFF,0X00,
0X00,0X07,0XF8,0X3F,0XC0,0X7F,0XFE,0X03,0XFC,0X7F,0XFF,0XFF,0XFF,0XFF,0XFF,0XFF,
0XFF,0XFF,0XFF,0X3F,0XF0,0X1F,0X80,0XFE,0X00,0X00,0X0F,0XF9,0XF8,0X03,0XFF,0XFC,
0X03,0XFE,0X7F,0XFF,0XFF,0XFF,0XFF,0XFF,0XFF,0XFF,0XFF,0XFF,0X1F,0XFE,0X0F,0XF0,
0X18,0X00,0X00,0X0F,0XFF,0X00,0X3F,0XFF,0XFC,0X01,0XFE,0X3F,0XFF,0XFF,0XFF,0XFF,
0XFF,0XFF,0XFF,0XFF,0XFF,0X9F,0XFF,0XC3,0XFF,0X00,0XFF,0X00,0X1F,0XFC,0X03,0XFF,
0XFF,0XFC,0X00,0XFF,0X3F,0XFF,0XFF,0XFF,0XFF,0XFF,0XFF,0XFF,0XFF,0XFF,0X8F,0X9F,
0XF0,0XFF,0XE0,0X07,0XE0,0X1F,0XFC,0XFF,0XFF,0XDF,0XFC,0X00,0XFF,0X1F,0XFF,0XFF,
0XFF,0XFF,0XFF,0XFF,0XFF,0XFF,0XFF,0X8F,0X80,0XFF,0XFF,0XFF,0X07,0XF0,0X1F,0XFF,
0X7F,0XFF,0X3F,0XF8,0X00,0X7F,0X1F,0XFF,0XFF,0XFF,0XFF,0XFF,0XFF,0XFF,0XFF,0XFF,
0XC7,0XC0,0X01,0XFF,0XFF,0XFF,0XFC,0X3F,0XFE,0X7F,0XFE,0X3F,0XF8,0X00,0X7F,0X8F,
0XFF,0XFF,0XFF,0XFF,0XFF,0XFF,0XFF,0XFF,0XFF,0XC7,0XFE,0X00,0X00,0X00,0X0F,0XFE,
0X3F,0XFC,0XC0,0X00,0X7F,0XF0,0X00,0X3F,0X8F,0XFF,0XFF,0XFF,0XFF,0XFF,0XFF,0XFF,
0XFF,0XFF,0XC3,0XFF,0XFC,0X00,0X00,0X0F,0XFF,0X1F,0XFC,0XC0,0X01,0XFF,0XF0,0X00,
0X3F,0XCF,0XFF,0XFF,0XFF,0XFF,0XFF,0XFF,0XFF,0XFF,0XFF,0XC1,0XFF,0XFF,0XFF,0XFF,
0XFF,0XFF,0X1F,0XF8,0XC0,0X03,0XFF,0XE0,0X00,0X3F,0XC7,0XFF,0XFF,0XFF,0XFF,0XFF,
0XFF,0XFF,0XFF,0XFF,0XC1,0XFF,0XFF,0XFF,0XFE,0XF3,0XFF,0X1F,0XF9,0XE0,0X0F,0XFF,
0XE0,0X00,0X1F,0XC7,0XFF,0XFF,0XFF,0XFF,0XFF,0XFF,0XFF,0XFF,0XFF,0XC0,0XFF,0XFF,
0XFF,0XFE,0X03,0XFF,0X9F,0XF1,0XF0,0X3F,0XFF,0XC0,0X00,0X1F,0XE7,0XFF,0XFF,0XFF,
0XFF,0XFF,0XFF,0XFF,0XFF,0XFF,0XC4,0X7F,0XFF,0XFF,0XFC,0X0F,0XFF,0X83,0XE3,0XF9,
0XFF,0XFF,0XC0,0X00,0X1F,0XE3,0XFF,0XFF,0XFF,0XFF,0XFF,0XFF,0XFF,0XFF,0XFF,0XC4,
0X7F,0XFF,0XFF,0XC0,0X0F,0XFF,0X00,0XC7,0XFF,0XFF,0XFF,0X80,0X00,0X0F,0XF3,0XFF,
0XFF,0XFF,0XFF,0XFF,0XFF,0XFF,0XFF,0XFF,0XC6,0X3F,0XFF,0XFC,0X03,0XC7,0XFE,0X00,
0X07,0XFF,0XFF,0XFF,0X00,0X00,0X0F,0XF1,0XFF,0XFF,0XFF,0XFF,0XFF,0XFF,0XFF,0XFF,
0XFF,0XC7,0X1F,0XF8,0X00,0X1F,0XE1,0XFC,0X10,0X0F,0XFF,0XFF,0XFF,0X00,0X00,0X0F,
0XF1,0XFF,0XFF,0XFF,0XFF,0XFF,0XFF,0XFF,0XFF,0XFF,0XC7,0X00,0X00,0X01,0XFF,0XF8,
0X3C,0X38,0X1F,0XFF,0XFF,0XFE,0X00,0X00,0X07,0XF9,0XFF,0XFF,0XFF,0XFF,0XFF,0XFF,
0XFF,0XFF,0XFF,0XC7,0X80,0X01,0XFF,0XFF,0X1C,0X00,0X78,0X7F,0XFF,0XFF,0XFC,0X00,
0X00,0X07,0XF8,0XFF,0XFF,0XFF,0XFF,0XFF,0XFF,0XFF,0XFF,0XFF,0XC7,0XC7,0XFF,0XFF,
0XFE,0X1F,0X00,0X00,0XFF,0XFF,0XFF,0XF8,0X60,0X00,0X07,0XF8,0XFF,0XFF,0XFF,0XFF,
0XFF,0XFF,0XFF,0XFF,0XFF,0XE7,0XE3,0XFF,0XFF,0XFE,0X0F,0XE0,0X03,0XFF,0XE7,0XFF,
0XF0,0XFE,0X00,0X07,0XFC,0XFF,0XFF,0XFF,0XFF,0XFF,0XFF,0XFF,0XFF,0XFF,0XE7,0XF1,
0XFF,0XFF,0XF8,0X0F,0XFF,0XFF,0XFF,0XF1,0XFF,0XE1,0XFF,0XF8,0XFF,0XFC,0X7F,0XFF,
0XFF,0XFF,0XFF,0XFF,0XFF,0XFF,0XFF,0XE7,0XF8,0XFF,0XFF,0XC0,0X1F,0XFF,0XFF,0XE7,
0XF8,0X7F,0XC3,0XFF,0XFF,0XFF,0XFC,0X7F,0XFF,0XFF,0XFF,0XFF,0XFF,0XFF,0XFF,0XFF,
0XE7,0XF0,0X3F,0XFE,0X00,0X3F,0XFF,0XFF,0XF3,0XFC,0X3F,0X87,0XFF,0XFF,0XFF,0XFE,
0X7F,0XFF,0XFF,0XFF,0XFF,0XFF,0XFF,0XFF,0XFF,0XE7,0XF0,0X1F,0XFE,0X00,0XFF,0XFF,
0XFF,0XF0,0XFC,0X1F,0X0F,0XFF,0XFF,0XFF,0XFE,0X3F,0XFF,0XFF,0XFF,0XFF,0XFF,0XFF,
0XFF,0XFF,0XE3,0XF0,0X0F,0XFF,0XFF,0XFF,0XFE,0X7F,0XF8,0X7E,0X0C,0X01,0XFF,0XFF,
0XFF,0XFE,0X3F,0XFF,0XFF,0XFF,0XFF,0XFF,0XFF,0XFF,0XFF,0XE3,0XF0,0X07,0XFF,0XFF,
0XFF,0XFE,0X7F,0XF8,0X3F,0X00,0X00,0X0F,0XFF,0XFF,0XE0,0X3F,0XFF,0XFF,0XFF,0XFF,
0XFF,0XFF,0XFF,0XFF,0XE3,0XF0,0X01,0XFF,0XFF,0XFF,0XFC,0X7F,0XF8,0X1F,0X00,0XF0,
0X00,0X00,0X00,0X00,0X3F,0XFF,0XFF,0XFF,0XFF,0XFF,0XFF,0XFF,0XFF,0XE3,0XF0,0X00,
0XFF,0XFF,0XFE,0X7C,0X7F,0XF8,0X0F,0X83,0XFF,0X00,0X00,0X00,0X03,0XFF,0XFF,0XFF,
0XFF,0XFF,0XFF,0XFF,0XFF,0XFF,0XE3,0XF0,0X00,0X3F,0XFF,0XFE,0X7C,0X7F,0XF8,0X06,
0X07,0XFF,0XFC,0X00,0X00,0XFF,0XFF,0XFF,0XFF,0XFF,0XFF,0XFF,0XFF,0XFF,0XFF,0XE3,
0XF0,0X00,0X0F,0XFF,0XFE,0X7C,0X7F,0XFC,0X00,0X1F,0XFF,0XFF,0XFF,0XFF,0XFF,0XFF,
0XFF,0XFF,0XFF,0XFF,0XFF,0XFF,0XFF,0XFF,0XF3,0XF8,0X00,0X01,0XFF,0XFC,0X7C,0X3F,
0XFC,0X00,0X7F,0XFF,0XFF,0XFF,0XFF,0XFF,0XFF,0XFF,0XFF,0XFF,0XFF,0XFF,0XFF,0XFF,
0XFF,0XF3,0XF8,0X00,0X00,0X7F,0XFC,0X7C,0X3F,0XFC,0X01,0XFF,0XFF,0XFF,0XFF,0XFF,
0XFF,0XFF,0XFF,0XFF,0XFF,0XFF,0XFF,0XFF,0XFF,0XFF,0XF3,0XF8,0X00,0X00,0X07,0XFC,
0X7C,0X3F,0XE0,0X0F,0XFF,0XFF,0XFF,0XFF,0XFF,0XFF,0XFF,0XFF,0XFF,0XFF,0XFF,0XFF,
0XFF,0XFF,0XFF,0XF3,0XF8,0X00,0X00,0X00,0X7C,0X7E,0X3C,0X00,0X7F,0XFF,0XFF,0XFF,
0XFF,0XFF,0XFF,0XFF,0XFF,0XFF,0XFF,0XFF,0XFF,0XFF,0XFF,0XFF,0XF1,0XF8,0X00,0X03,
0X80,0X00,0X00,0X00,0X03,0XFF,0XFF,0XFF,0XFF,0XFF,0XFF,0XFF,0XFF,0XFF,0XFF,0XFF,
0XFF,0XFF,0XFF,0XFF,0XFF,0XF1,0XFC,0X00,0X03,0XF8,0X00,0X00,0X00,0X3F,0XFF,0XFF,
0XFF,0XFF,0XFF,0XFF,0XFF,0XFF,0XFF,0XFF,0XFF,0XFF,0XFF,0XFF,0XFF,0XFF,0XF1,0XFC,
0X00,0X07,0XFF,0X10,0X00,0X1F,0XFF,0XFF,0XFF,0XFF,0XFF,0XFF,0XFF,0XFF,0XFF,0XFF,
0XFF,0XFF,0XFF,0XFF,0XFF,0XFF,0XFF,0XF1,0XFC,0X00,0X0F,0XFE,0X3F,0XFF,0XFF,0XFF,
0XFF,0XFF,0XFF,0XFF,0XFF,0XFF,0XFF,0XFF,0XFF,0XFF,0XFF,0XFF,0XFF,0XFF,0XFF,0XFF,
0XF9,0XFC,0X00,0X1F,0XFC,0X7F,0XFF,0XFF,0XFF,0XFF,0XFF,0XFF,0XFF,0XFF,0XFF,0XFF,
0XFF,0XFF,0XFF,0XFF,0XFF,0XFF,0XFF,0XFF,0XFF,0XF9,0XFE,0X00,0X3F,0XF8,0X7F,0XFF,
0XFF,0XFF,0XFF,0XFF,0XFF,0XFF,0XFF,0XFF,0XFF,0XFF,0XFF,0XFF,0XFF,0XFF,0XFF,0XFF,
0XFF,0XFF,0XF8,0XFE,0X00,0X7F,0XF8,0XFF,0XFF,0XFF,0XFF,0XFF,0XFF,0XFF,0XFF,0XFF,
0XFF,0XFF,0XFF,0XFF,0XFF,0XFF,0XFF,0XFF,0XFF,0XFF,0XFF,0XF8,0XFE,0X00,0XFF,0XF1,
0XFF,0XFF,0XFF,0XFF,0XFF,0XFF,0XFF,0XFF,0XFF,0XFF,0XFF,0XFF,0XFF,0XFF,0XFF,0XFF,
0XFF,0XFF,0XFF,0XFF,0XF8,0XFF,0X01,0XFF,0XE3,0XFF,0XFF,0XFF,0XFF,0XFF,0XFF,0XFF,
0XFF,0XFF,0XFF,0XFF,0XFF,0XFF,0XFF,0XFF,0XFF,0XFF,0XFF,0XFF,0XFF,0XFC,0XFF,0X03,
0XFF,0XC7,0XFF,0XFF,0XFF,0XFF,0XFF,0XFF,0XFF,0XFF,0XFF,0XFF,0XFF,0XFF,0XFF,0XFF,
0XFF,0XFF,0XFF,0XFF,0XFF,0XFF,0XFC,0XFF,0X07,0XFF,0X0F,0XFF,0XFF,0XFF,0XFF,0XFF,
0XFF,0XFF,0XFF,0XFF,0XFF,0XFF,0XFF,0XFF,0XFF,0XFF,0XFF,0XFF,0XFF,0XFF,0XFF,0XFC,
0X7F,0X9F,0XFE,0X1F,0XFF,0XFF,0XFF,0XFF,0XFF,0XFF,0XFF,0XFF,0XFF,0XFF,0XFF,0XFF,
0XFF,0XFF,0XFF,0XFF,0XFF,0XFF,0XFF,0XFF,0XFC,0X7F,0XFF,0XFC,0X3F,0XFF,0XFF,0XFF,
0XFF,0XFF,0XFF,0XFF,0XFF,0XFF,0XFF,0XFF,0XFF,0XFF,0XFF,0XFF,0XFF,0XFF,0XFF,0XFF,
0XFF,0XFE,0X7F,0XFF,0XF8,0X7F,0XFF,0XFF,0XFF,0XFF,0XFF,0XFF,0XFF,0XFF,0XFF,0XFF,
0XFF,0XFF,0XFF,0XFF,0XFF,0XFF,0XFF,0XFF,0XFF,0XFF,0XFE,0X7F,0XFF,0XE1,0XFF,0XFF,
0XFF,0XFF,0XFF,0XFF,0XFF,0XFF,0XFF,0XFF,0XFF,0XFF,0XFF,0XFF,0XFF,0XFF,0XFF,0XFF,
0XFF,0XFF,0XFF,0XFE,0X3F,0XFF,0XC3,0XFF,0XFF,0XFF,0XFF,0XFF,0XFF,0XFF,0XFF,0XFF,
0XFF,0XFF,0XFF,0XFF,0XFF,0XFF,0XFF,0XFF,0XFF,0XFF,0XFF,0XFF,0XFE,0X3F,0XFF,0X0F,
0XFF,0XFF,0XFF,0XFF,0XFF,0XFF,0XFF,0XFF,0XFF,0XFF,0XFF,0XFF,0XFF,0XFF,0XFF,0XFF,
0XFF,0XFF,0XFF,0XFF,0XFF,0XFF,0X3F,0XFC,0X1F,0XFF,0XFF,0XFF,0XFF,0XFF,0XFF,0XFF,
0XFF,0XFF,0XFF,0XFF,0XFF,0XFF,0XFF,0XFF,0XFF,0XFF,0XFF,0XFF,0XFF,0XFF,0XFF,0X1F,
0XF8,0X7F,0XFF,0XFF,0XFF,0XFF,0XFF,0XFF,0XFF,0XFF,0XFF,0XFF,0XFF,0XFF,0XFF,0XFF,
0XFF,0XFF,0XFF,0XFF,0XFF,0XFF,0XFF,0XFF,0X9F,0XE0,0XFF,0XFF,0XFF,0XFF,0XFF,0XFF,
0XFF,0XFF,0XFF,0XFF,0XFF,0XFF,0XFF,0XFF,0XFF,0XFF,0XFF,0XFF,0XFF,0XFF,0XFF,0XFF,
0XFF,0X8F,0X03,0XFF,0XFF,0XFF,0XFF,0XFF,0XFF,0XFF,0XFF,0XFF,0XFF,0XFF,0XFF,0XFF,
0XFF,0XFF,0XFF,0XFF,0XFF,0XFF,0XFF,0XFF,0XFF,0XFF,0X8C,0X0F,0XFF,0XFF,0XFF,0XFF,
0XFF,0XFF,0XFF,0XFF,0XFF,0XFF,0XFF,0XFF,0XFF,0XFF,0XFF,0XFF,0XFF,0XFF,0XFF,0XFF,
0XFF,0XFF,0XFF,0XC0,0X3F,0XFF,0XFF,0XFF,0XFF,0XFF,0XFF,0XFF,0XFF,0XFF,0XFF,0XFF,
0XFF,0XFF,0XFF,0XFF,0XFF,0XFF,0XFF,0XFF,0XFF,0XFF,0XFF,0XFF,0XE0,0XFF,0XFF,0XFF,
0XFF,0XFF,0XFF,0XFF,0XFF,0XFF,0XFF,0XFF,0XFF,0XFF,0XFF,0XFF,0XFF,0XFF,0XFF,0XFF,
0XFF,0XFF,0XFF,0XFF,0XFF,0XE3,0XFF,0XFF,0XFF,0XFF,0XFF,0XFF,0XFF,0XFF,0XFF,0XFF,
0XFF,0XFF,0XFF,0XFF,0XFF,0XFF,0XFF,0XFF,};

uint8_t nfcbuf2[5000] = { /* 0X00,0X01,0XC8,0X00,0XC8,0X00, */
0XFF,0XFF,0XFF,0XFF,0XFF,0XFF,0XFF,0XFF,0XFF,0XFF,0XFF,0XFF,0XFF,0XFF,0XFF,0XFF,
0XFF,0XFF,0XFF,0XFF,0XFF,0XFF,0XFF,0XFF,0XFF,0XFF,0XFF,0XFF,0XFF,0XFF,0XFF,0XFF,
0XFF,0XFF,0XFF,0XFF,0XFF,0XFF,0XFF,0XFF,0XFF,0XFF,0XFF,0XFF,0XFF,0XFF,0XFF,0XFF,
0XFF,0XFF,0XFF,0XFF,0XFF,0XFF,0XFF,0XFF,0XFF,0XFF,0XFF,0XFF,0XFF,0XFF,0XFF,0XFF,
0XFF,0XFF,0XFF,0XFF,0XFF,0XFF,0XFF,0XFF,0XFF,0XFF,0XFF,0XFF,0XFF,0XFF,0XFF,0XFF,
0XFF,0XFF,0XFF,0XFF,0XFF,0XFF,0XFF,0XFF,0XFF,0XFF,0XFF,0XFF,0XFF,0XFF,0XFF,0XFF,
0XFF,0XFF,0XFF,0XFF,0XFF,0XFF,0XFF,0XFF,0XFF,0XFF,0XFF,0XFF,0XFF,0XFF,0XFF,0XFF,
0XFF,0XFF,0XFF,0XFF,0XFF,0XFF,0XFF,0XFF,0XFF,0XFF,0XFF,0XFF,0XFF,0XFF,0XFF,0XFF,
0XFF,0XFF,0XFF,0XFF,0XFF,0XFF,0XFF,0XFF,0XFF,0XFF,0XFF,0XFF,0XFF,0XFF,0XFF,0XFF,
0XFF,0XFF,0XFF,0XFF,0XFF,0XFF,0XFF,0XFF,0XFF,0XFF,0XFF,0XFF,0XFF,0XFF,0XFF,0XFF,
0XFF,0XFF,0XFF,0XFF,0XFF,0XFF,0XFF,0XFF,0XFF,0XFF,0XFF,0XFF,0XFF,0XFF,0XFF,0XFF,
0XFF,0XFF,0XFF,0XFF,0XFF,0XFF,0XFF,0XFF,0XFF,0XFF,0XFF,0XFF,0XFF,0XFF,0XFF,0XFF,
0XFF,0XFF,0XFF,0XFF,0XFF,0XFF,0XFF,0XFF,0XFF,0XFF,0XFF,0XFF,0XFF,0XFF,0XFF,0XFF,
0XFF,0XFF,0XFF,0XFF,0XFF,0XFF,0XFF,0XFF,0XFF,0XFF,0XFF,0XFF,0XFF,0XFF,0XFF,0XFF,
0XFF,0XFF,0XFF,0XFF,0XFF,0XFF,0XFF,0XFF,0XFF,0XFF,0XFF,0XFF,0XFF,0XFF,0XFF,0XFF,
0XFF,0XFF,0XFF,0XFF,0XFF,0XFF,0XFF,0XFF,0XFF,0XFF,0XFF,0XFF,0XFF,0XFF,0XFF,0XFF,
0XFF,0XFF,0XFF,0XFF,0XFF,0XFF,0XFF,0XFF,0XFF,0XFF,0XFF,0XFF,0XFF,0XFF,0XFF,0XFF,
0XFF,0XFF,0XFF,0XFF,0XFF,0XFF,0XFF,0XFF,0XFF,0XFF,0XFF,0XFF,0XFF,0XFF,0XFF,0XFF,
0XFF,0XFF,0XFF,0XFF,0XFF,0XFF,0XFF,0XFF,0XFF,0XFF,0XFF,0XFF,0XFF,0XFF,0XFF,0XFF,
0XFF,0XFF,0XFF,0XFF,0XFF,0XFF,0XFF,0XFF,0XFF,0XFF,0XFF,0XFF,0XFF,0XFF,0XFF,0XFF,
0XFF,0XFF,0XFF,0XFF,0XFF,0XFF,0XFF,0XFF,0XFF,0XFF,0XFF,0XFF,0XFF,0XFF,0XFF,0XFF,
0XFF,0XFF,0XFF,0XFF,0XFF,0XFF,0XFF,0XFF,0XFF,0XFF,0XFF,0XFF,0XFF,0XFF,0XFF,0XFF,
0XFF,0XFF,0XFF,0XFF,0XFF,0XFF,0XFF,0XFF,0XFF,0XFF,0XFF,0XFF,0XFF,0XFF,0XFF,0XFF,
0XFF,0XFF,0XFF,0XFF,0XFF,0XFF,0XFF,0XFF,0XFF,0XFF,0XFF,0XFF,0XFF,0XFF,0XFF,0XFF,
0XFF,0XFF,0XFF,0XFF,0XFF,0XFF,0XFF,0XFF,0XFF,0XFF,0XFF,0XFF,0XFF,0XFF,0XFF,0XFF,
0XFF,0XFF,0XFF,0XFF,0XFF,0XFF,0XFF,0XFF,0XFF,0XFF,0XFF,0XFF,0XFF,0XFF,0XFF,0XFF,
0XFF,0XFF,0XFF,0XFF,0XFF,0XFF,0XFF,0XFF,0XFF,0XFF,0XFF,0XFF,0XFF,0XFF,0XFF,0XFF,
0XFF,0XFF,0XFF,0XFF,0XFF,0XFF,0XFF,0XFF,0XFF,0XFF,0XFF,0XFF,0XFF,0XFF,0XFF,0XFF,
0XFF,0XFF,0XFF,0XFF,0XFF,0XFF,0XFF,0XFF,0XFF,0XFF,0XFF,0XFF,0XFF,0XFF,0XFF,0XFF,
0XFF,0XFF,0XFF,0XFF,0XFF,0XFF,0XFF,0XFF,0XFF,0XFF,0XFF,0XFF,0XFF,0XFF,0XFF,0XFF,
0XFF,0XFF,0XFF,0XFF,0XFF,0XFF,0XFF,0XFF,0XFF,0XFF,0XFF,0XFF,0XFF,0XFF,0XFF,0XFF,
0XFF,0XFF,0XFF,0XFF,0XFF,0XFF,0XFF,0XFF,0XFF,0XFF,0XFF,0XFF,0XFF,0XFF,0XFF,0XFF,
0XFF,0XFF,0XFF,0XFF,0XFF,0XFF,0XFF,0XFF,0XFF,0XFF,0XFF,0XFF,0XFF,0XFF,0XFF,0XFF,
0XFF,0XFF,0XFF,0XFF,0XFF,0XFF,0XFF,0XFF,0XFF,0XFF,0XFF,0XFF,0XFF,0XFF,0XFF,0XFF,
0XFF,0XFF,0XFF,0XFF,0XFF,0XFF,0XFF,0XFF,0XFF,0XFF,0XFF,0XFF,0XFF,0XFF,0XFF,0XFF,
0XFF,0XFF,0XFF,0XFF,0XFF,0XFF,0XFF,0XFF,0XFF,0XFF,0XFF,0XFF,0XFF,0XFF,0XFF,0XFF,
0XFF,0XFF,0XFF,0XFF,0XFF,0XFF,0XFF,0XFF,0XFF,0XFF,0XFF,0XFF,0XFF,0XFF,0XFF,0XFF,
0XFF,0XFF,0XFF,0XFF,0XFF,0XFF,0XFF,0XFF,0XFF,0XFF,0XFF,0XFF,0XFF,0XFF,0XFF,0XFF,
0XFF,0XFF,0XFF,0XFF,0XFF,0XFF,0XFF,0XFF,0XFF,0XFF,0XFF,0XFF,0XFF,0XFF,0XFF,0XFF,
0XFF,0XFF,0XFF,0XFF,0XFF,0XFF,0XFF,0XFF,0XFF,0XFF,0XFF,0XFF,0XFF,0XFF,0XFF,0XFF,
0XFF,0XFF,0XFF,0XFF,0XFF,0XFF,0XFF,0XFF,0XFF,0XFF,0XFF,0XFF,0XFF,0XFF,0XFF,0XFF,
0XFF,0XFF,0XFF,0XFF,0XFF,0XFF,0XFF,0XFF,0XFF,0XFF,0XFF,0XFF,0XFF,0XFF,0XFF,0XFF,
0XFF,0XFF,0XFF,0XFF,0XFF,0XFF,0XFF,0XFF,0XFF,0XFF,0XFF,0XFF,0XFF,0XFF,0XFF,0XFF,
0XFF,0XFF,0XFF,0XFF,0XFF,0XFF,0XFF,0XFF,0XFF,0XFF,0XFF,0XFF,0XFF,0XFF,0XFF,0XFF,
0XFF,0XFF,0XFF,0XFF,0XFF,0XFF,0XFF,0XFF,0XFF,0XFF,0XFF,0XFF,0XFF,0XFF,0XFF,0XFF,
0XFF,0XFF,0XFF,0XFF,0XFF,0XFF,0XFF,0XFF,0XFF,0XFF,0XFF,0XFF,0XFF,0XFF,0XFF,0XFF,
0XFF,0XFF,0XFF,0XFF,0XFF,0XFF,0XFF,0XFF,0XFF,0XFF,0XFF,0XFF,0XFF,0XFF,0XFF,0XFF,
0XFF,0XFF,0XFF,0XFF,0XFF,0XFF,0XFF,0XFF,0XFF,0XFF,0XFF,0XFF,0XFF,0XFF,0XFF,0XFF,
0XFF,0XFF,0XFF,0XFF,0XFF,0XFF,0XFF,0XFF,0XFF,0XFF,0XFF,0XFF,0XFF,0XFF,0XFF,0XFF,
0XFF,0XFF,0XFF,0XFF,0XFF,0XFF,0XFF,0XFF,0XFF,0XFF,0XFF,0XFF,0XFF,0XFF,0XFF,0XFF,
0XFF,0XFF,0XFF,0XFF,0XFF,0XFF,0XFF,0XFF,0XFF,0XFF,0XFF,0XFF,0XFF,0XFF,0XFF,0XFF,
0XFF,0XFF,0XFF,0XFF,0XFF,0XFF,0XFF,0XFF,0XFF,0XFF,0XFF,0XFF,0XFF,0XFF,0XFF,0XFF,
0XFF,0XFF,0XFF,0XFF,0XFF,0XFF,0XFF,0XFF,0XFF,0XFF,0XFF,0XFF,0XFF,0XFF,0XFF,0XFF,
0XFF,0XFF,0XFF,0XFF,0XFF,0XFF,0XFF,0XFF,0XFF,0XFF,0XFF,0XFF,0XFF,0XFF,0XFF,0XFF,
0XFF,0XFF,0XFF,0XFF,0XFF,0XFF,0XFF,0XFF,0XFF,0XFF,0XFF,0XFF,0XFF,0XFF,0XFF,0XFF,
0XFF,0XFF,0XFF,0XFF,0XFF,0XFF,0XFF,0XFF,0XFF,0XFF,0XFF,0XFF,0XFF,0XFF,0XFF,0XFF,
0XFF,0XFF,0XFF,0XFF,0XFF,0XFF,0XFF,0XFF,0XFF,0XFF,0XFF,0XFF,0XFF,0XFF,0XFF,0XFF,
0XFF,0XFF,0XFF,0XFF,0XFF,0XFF,0XFF,0XFF,0XFF,0XFF,0XFF,0XFF,0XFF,0XFF,0XFF,0XFF,
0XFF,0XFF,0XFF,0XFF,0XFF,0XFF,0XFF,0XFF,0XFF,0XFF,0XFF,0XFF,0XFF,0XFF,0XFF,0XFF,
0XFF,0XFF,0XFF,0XFF,0XFF,0XFF,0XFF,0XFF,0XFF,0XFF,0XFF,0XFF,0XFF,0XFF,0XFF,0XFF,
0XFF,0XFF,0XFF,0XFF,0XFF,0XFF,0XFF,0XFF,0XFF,0XFF,0XFF,0XFF,0XFF,0XFF,0XFF,0XFF,
0XFF,0XFF,0XFF,0XFF,0XFF,0XFF,0XFF,0XFF,0XFF,0XFF,0XFF,0XFF,0XFF,0XFF,0XFF,0XFF,
0XFF,0XFF,0XFF,0XFF,0XFF,0XFF,0XFF,0XFF,0XFF,0XFF,0XFF,0XFF,0XFF,0XFF,0XFF,0XFF,
0XFF,0XFF,0XFF,0XFF,0XFF,0XFF,0XFF,0XFF,0XFF,0XFF,0XFF,0XFF,0XFF,0XFF,0XFF,0XFF,
0XFF,0XFF,0XFF,0XFF,0XFF,0XFF,0XFF,0XFF,0XFF,0XFF,0XFF,0XFF,0XFF,0XFF,0XFF,0XFF,
0XFF,0XFF,0XFF,0XFF,0XFF,0XFF,0XFF,0XFF,0XFF,0XFF,0XFF,0XFF,0XFF,0XFF,0XFF,0XFF,
0XFF,0XFF,0XFF,0XFF,0XFF,0XFF,0XFF,0XFF,0XFF,0XFF,0XFF,0XFF,0XFF,0XFF,0XFF,0XFF,
0XFF,0XFF,0XFF,0XFF,0XFF,0XFF,0XFF,0XFF,0XFF,0XFF,0XFF,0XFF,0XFF,0XFF,0XFF,0XFF,
0XFF,0XFF,0XFF,0XFF,0XFF,0XFF,0XFF,0XFF,0XFF,0XFF,0XFF,0XFF,0XFF,0XFF,0XFF,0XFF,
0XFF,0XFF,0XFF,0XFD,0X7F,0XFF,0XFF,0XFF,0XFF,0XFF,0XFF,0XFF,0XFF,0XFF,0XFF,0XFF,
0XFF,0XFF,0XFF,0XFF,0XFF,0XFF,0XFF,0XFF,0XFF,0XFF,0XFF,0XFF,0XF8,0X3F,0XFF,0XEE,
0XFF,0XFF,0XFF,0XEA,0XFF,0XFF,0XFF,0XFF,0XFF,0XFF,0XFF,0XFF,0XFF,0XFF,0XFF,0XFF,
0XFF,0XFF,0XFF,0XFF,0XFF,0XF0,0X1F,0XD5,0X11,0X15,0X5F,0XFF,0XC0,0X7F,0XFF,0XFF,
0XFF,0XFF,0XFF,0XFF,0XFF,0XFF,0XFF,0XFF,0XFF,0XFF,0XFF,0XFF,0XFF,0XFF,0XC0,0X88,
0X00,0X00,0X00,0X00,0X0B,0X80,0X1F,0XFF,0XFF,0XFF,0XFF,0XFF,0XFF,0XFF,0XFF,0XFF,
0XFF,0XFF,0XFF,0XFF,0XFF,0XFF,0XFF,0XC7,0XC0,0X40,0X44,0X44,0X44,0X05,0XC4,0X5F,
0XFF,0XFF,0XFF,0XFF,0XFF,0XFF,0XFF,0XFF,0XFF,0XFF,0XFF,0XFF,0XFF,0XFF,0XFF,0XFF,
0X82,0X80,0X2A,0XAA,0XAA,0XAA,0X00,0X0E,0X07,0XFF,0XFF,0XFF,0XFF,0XFF,0XFF,0XFF,
0XFF,0XFF,0XFF,0XFF,0XFF,0XFF,0XFF,0XFF,0XFF,0X0F,0XDF,0XFF,0XFF,0XFF,0XFF,0XFD,
0X1F,0XD7,0XFF,0XFF,0XFF,0XFF,0XFF,0XFF,0XFF,0XFF,0XFF,0XFF,0XFF,0XFF,0XFF,0XFF,
0XFF,0XFE,0X0B,0X8B,0XAA,0XAA,0XBA,0XAB,0XBB,0X8A,0XA1,0XFF,0XFF,0XFF,0XFF,0XFF,
0XFF,0XFF,0XFF,0XFF,0XFF,0XFF,0XFF,0XFF,0XFF,0XFF,0XFE,0X5F,0X9F,0XFF,0XD5,0X7F,
0XFF,0XFF,0XCF,0XF5,0XFF,0XFF,0XFF,0XFF,0XFF,0XFF,0XFF,0XFF,0XFF,0XFF,0XFF,0XFF,
0XFF,0XFF,0XFF,0XFE,0X3E,0XAE,0XEE,0X00,0X02,0XEE,0XEE,0XEE,0XF8,0XFF,0XFF,0XFF,
0XFF,0XFF,0XFF,0XFF,0XFF,0XFF,0XFF,0XFF,0XFF,0XFF,0XFF,0XFF,0XFC,0X7F,0XFF,0XFD,
0X55,0X51,0XFF,0XFF,0XFF,0XFD,0X7F,0XFF,0XFF,0XFF,0XFF,0XFF,0XFF,0XFF,0XFF,0XFF,
0XFF,0XFF,0XFF,0XFF,0XFF,0XF8,0X2A,0XAA,0XB8,0X0A,0X88,0X3A,0XAA,0XAA,0XA8,0X3F,
0XFF,0XFF,0XFF,0XFF,0XFF,0XFF,0XFF,0XFF,0XFF,0XFF,0XFF,0XFF,0XFF,0XFF,0XFC,0X7F,
0XFF,0XF5,0X77,0X75,0X7F,0XFF,0XFF,0XFD,0X7F,0XFF,0XFF,0XFF,0XFF,0XFF,0XFF,0XFF,
0XFF,0XFF,0XFF,0XFF,0XFF,0XFF,0XFF,0XF8,0XEE,0XEE,0XE2,0XAA,0XAA,0X2A,0XEE,0XEE,
0XEE,0X3F,0XFF,0XFF,0XFF,0XFF,0XFF,0XFF,0XFF,0XFF,0XFF,0XFF,0XFF,0XFF,0XFF,0XFF,
0XF9,0XFF,0XFF,0XF5,0X55,0X55,0X55,0XFF,0XFD,0X7F,0X1F,0XFF,0XFF,0XFF,0XFF,0XFF,
0XFF,0XFF,0XFF,0XFF,0XFF,0XFF,0XFF,0XFF,0XFF,0XF8,0XA8,0XAA,0XA2,0XAA,0XAA,0X08,
0XAA,0XAA,0X3A,0X80,0XBF,0XFF,0XFF,0XFF,0XFF,0XFF,0XFF,0XFF,0XFF,0XFF,0XFF,0XFF,
0XFF,0XFF,0XF1,0XFD,0XFF,0XD5,0X55,0X55,0X55,0X7F,0XFF,0X5F,0X54,0X55,0XFF,0XFF,
0XFF,0XFF,0XFF,0XFF,0XFF,0XFF,0XFF,0XFF,0XFF,0XFF,0XFF,0XF8,0XE2,0XEA,0XA2,0XAA,
0XAA,0X22,0X2E,0XEE,0X8A,0X0A,0X00,0X03,0XFF,0XFF,0XFF,0XFF,0XFF,0XFF,0XFF,0XFF,
0XFF,0XFF,0XFF,0XFF,0XF9,0XC1,0XF5,0X55,0X55,0X55,0X55,0X5F,0XFF,0XD5,0X5F,0X50,
0X13,0XFF,0XFF,0XFF,0XFF,0XFF,0XFF,0XFF,0XFF,0XFF,0XFF,0XFF,0XFF,0XF8,0X02,0XA8,
0X8A,0XAA,0XAA,0X88,0X8A,0XAA,0XA8,0X0B,0XAA,0X83,0XFF,0XFF,0XFF,0XFF,0XFF,0XFF,
0XFF,0XFF,0XFF,0XFF,0XFF,0XFF,0XFC,0X07,0XFF,0XD5,0X55,0X55,0X5D,0X55,0XFF,0XFF,
0XD7,0XFF,0XF7,0XFF,0XFF,0XFF,0XFF,0XFF,0XFF,0XFF,0XFF,0XFF,0XFF,0XFF,0XFF,0XFE,
0X22,0XEE,0XEA,0XAA,0XAA,0X8A,0XAA,0XEE,0XEE,0X88,0XBE,0XE3,0XFF,0XFF,0XFF,0XFF,
0XFF,0XFF,0XFF,0XFF,0XFF,0XFF,0XFF,0XFF,0XFF,0XF1,0XFF,0XD5,0X55,0X55,0X55,0X7F,
0XFF,0XFF,0XDC,0X1F,0XC7,0XFF,0XFF,0XFF,0XFF,0XFF,0XFF,0XFF,0XFF,0XFF,0XFF,0XFF,
0XFF,0XFF,0XE3,0XA8,0X0A,0XAA,0XAA,0X82,0XAA,0XAA,0XAA,0X8E,0X83,0X83,0XFF,0XFF,
0XFF,0XFF,0XFF,0XFF,0XFF,0XFF,0XFF,0XFF,0XFF,0XFF,0XFF,0XF5,0XF5,0X57,0X55,0X55,
0X55,0X57,0XFF,0XFF,0XDF,0XF1,0XC7,0XFF,0XFF,0XFF,0XFF,0XFF,0XFF,0XFF,0XFF,0XFF,
0XFF,0XFF,0XFF,0XFF,0XE3,0XE2,0X8A,0XAA,0XAA,0XAA,0X22,0XEE,0XEE,0X8F,0XF0,0X8F,
0XFF,0XFF,0XFF,0XFF,0XFF,0XFF,0XFF,0XFF,0XFF,0XFF,0XFF,0XFF,0XFF,0XF1,0XD7,0XD5,
0X55,0X55,0X55,0XF5,0XFF,0XFF,0X9F,0XF3,0X9F,0XFF,0XFF,0XFF,0XFF,0XFF,0XFF,0XFF,
0XFF,0XFF,0XFF,0XFF,0XFF,0XFF,0X82,0XAB,0X8A,0X8A,0XAA,0X80,0XB8,0XAA,0XAB,0X8F,
0XC3,0X82,0XFF,0XFF,0XFF,0XFF,0XFF,0XFF,0XFF,0XFF,0XFF,0XFF,0XFF,0XFF,0XFC,0X07,
0XFF,0X55,0X75,0X57,0X57,0XFD,0XFF,0XFF,0X1F,0XC7,0X00,0X7F,0XFF,0XFF,0XFF,0XFF,
0XFF,0XFF,0XFF,0XFF,0XFF,0XFF,0XFF,0XE0,0X2E,0XEE,0X22,0XAA,0XAA,0XAE,0XEE,0XEE,
0XEE,0X3F,0X8E,0XA0,0X0B,0XFF,0XFF,0XFF,0XFF,0XFF,0XFF,0XFF,0XFF,0XFF,0XFF,0XFF,
0XC1,0XFF,0XFF,0X55,0X55,0X55,0X5F,0XFF,0XFF,0XFF,0X1F,0X1F,0XFD,0X01,0XFF,0XFF,
0XFF,0XFF,0XFF,0XFF,0XFF,0XFF,0XFF,0XFF,0XFF,0X83,0XAA,0XAB,0XA8,0X00,0X00,0X02,
0XAA,0XAA,0XAB,0X8F,0X83,0XBE,0X80,0X1F,0XFF,0XFF,0XFF,0XFF,0XFF,0XFF,0XFF,0XFF,
0XFF,0XFF,0X47,0XFF,0XFF,0XFF,0X55,0X55,0X57,0XFF,0XFF,0XFF,0XC7,0XC5,0XFF,0XF4,
0X5F,0XFF,0XFF,0XFF,0XFF,0XFF,0XFF,0XFF,0XFF,0XFF,0XFE,0X0E,0XEE,0XEE,0XEE,0XEA,
0XAA,0XFE,0XEE,0XEE,0XEE,0XE3,0XE0,0X7E,0XFE,0X0F,0XFF,0XFF,0XFF,0XFF,0XFF,0XFF,
0XFF,0XFF,0XFF,0XFD,0X1F,0XFF,0XFF,0XFF,0XFF,0XFF,0XFF,0XFF,0XFF,0XFF,0XF1,0XFC,
0X1F,0XFF,0X9F,0XFF,0XFF,0XFF,0XFF,0XFF,0XFF,0XFF,0XFF,0XFF,0XF8,0X3B,0XBA,0XAA,
0XAA,0XAA,0XAB,0XBB,0XBB,0XBB,0XAA,0XB8,0XFE,0X0B,0XBB,0X8F,0XFF,0XFF,0XFF,0XFF,
0XFF,0XFF,0XFF,0XFF,0XFF,0XFC,0X7F,0XFF,0XFF,0XFF,0XFF,0XFF,0XFF,0XFF,0XFF,0XFF,
0XFC,0X7F,0XC7,0XFF,0X1F,0XFF,0XFF,0XFF,0XFF,0XFF,0XFF,0XFF,0XFF,0XFF,0XF0,0XAA,
0XEE,0XEE,0XEE,0XEE,0XEE,0XEE,0XEE,0XEA,0XAE,0XE8,0X7F,0XE0,0XEE,0X0F,0XFF,0XFF,
0XFF,0XFF,0XFF,0XFF,0XFF,0XFF,0XFF,0XF1,0XD5,0XFF,0XFF,0XFF,0XFF,0XFF,0XFF,0XFF,
0XD5,0X5F,0XFC,0X7F,0XFC,0XFF,0X1F,0XFF,0XFF,0XFF,0XFF,0XFF,0XFF,0XFF,0XFF,0XFF,
0XE0,0XA8,0XBA,0XAA,0XAA,0XBA,0XAB,0XBB,0XBB,0X8A,0XAB,0XAE,0X3F,0XF8,0XBA,0X1F,
0XFF,0XFF,0XFF,0XFF,0XFF,0XFF,0XFF,0XFF,0XFF,0XF5,0X55,0X7F,0XFF,0XFF,0XFF,0XFF,
0XFF,0XFF,0X55,0X77,0XFE,0X3F,0XF9,0XFF,0X3F,0XFF,0XFF,0XFF,0XFF,0XFF,0XFF,0XFF,
0XFF,0XFF,0XE2,0XAA,0XAE,0XEE,0XEE,0XEE,0XEE,0XEE,0XEE,0XAA,0XAA,0XEE,0X3F,0XF1,
0XEE,0X3F,0XFF,0XFF,0XFF,0XFF,0XFF,0XFF,0XFF,0XFF,0XFF,0XF1,0X55,0X7F,0XFF,0XFF,
0XFF,0XFF,0XFF,0XFF,0X55,0X55,0XFF,0X1F,0XF1,0XFF,0X7F,0XFF,0XFF,0XFF,0XFF,0XFF,
0XFF,0XFF,0XFF,0XFF,0XE0,0XAA,0XBB,0XBA,0XAA,0XAB,0XBB,0XBB,0XBA,0XAA,0XAA,0XAA,
0X0F,0XE3,0XBE,0X3F,0XFF,0XFF,0XFF,0XFF,0XFF,0XFF,0XFF,0XFF,0XFF,0XF5,0X55,0X7F,
0XFF,0XFF,0XFF,0XFF,0XFF,0XFF,0X57,0X55,0XFF,0X5F,0XE7,0XFE,0X57,0XFF,0XFF,0XFF,
0XFF,0XFF,0XFF,0XFF,0XFF,0XFF,0XE0,0XAA,0XAE,0XEE,0XEE,0XEE,0XEE,0XEE,0XEE,0XAA,
0XAA,0XEE,0X0F,0XE6,0XEE,0X00,0X2A,0XFF,0XFF,0XFF,0XFF,0XFF,0XFF,0XFF,0XFF,0XF1,
0X55,0X7F,0XFF,0XFF,0XFF,0XFF,0XFF,0XFF,0X55,0X55,0XFF,0X1F,0XCF,0XFF,0X40,0X00,
0X15,0XFF,0XFF,0XFF,0XFF,0XFF,0XFF,0XFF,0XF0,0XAA,0XBB,0XBB,0XBB,0XBB,0XBB,0XBB,
0XBA,0XAA,0XAA,0XBB,0X8F,0X8B,0XBB,0XE8,0X00,0X00,0X0F,0XFF,0XFF,0XFF,0XFF,0XFF,
0XFF,0XF1,0X55,0X7F,0XFF,0XFF,0XFF,0XFF,0XFF,0XFF,0X55,0X55,0XFF,0X5F,0XDF,0XFF,
0XFF,0X44,0X44,0X5F,0XFF,0XFF,0XFF,0XFF,0XFF,0XFF,0XF8,0XAA,0XEE,0XEE,0XEE,0XEE,
0XEE,0XEE,0XEE,0XAA,0XAA,0XEF,0X8F,0X8E,0XEE,0XEF,0X80,0X00,0X0F,0XFF,0XFF,0XFF,
0XFF,0XFF,0XFF,0XFD,0X55,0XFF,0XFF,0XFF,0XFF,0XFF,0XFF,0XFF,0XD5,0X55,0XFF,0X9F,
0X1F,0XFF,0XFF,0X11,0X11,0X1F,0XFF,0XFF,0XFF,0XFF,0XFF,0XFF,0XFC,0X2B,0XBB,0XBB,
0XBB,0XBB,0XBB,0XBB,0XBB,0XAA,0XAB,0XBB,0X8F,0X3B,0XBB,0XBB,0X80,0X00,0X0F,0XFF,
0XFF,0XFF,0XFF,0XFF,0XFF,0XFF,0X7F,0XFF,0XFF,0XFF,0XFF,0XFF,0XFF,0XFF,0XF5,0X5F,
0XFF,0X5F,0X7F,0XFF,0XFF,0XC4,0X44,0X5F,0XFF,0XFF,0XFF,0XFF,0XFF,0XFF,0XFF,0X3E,
0XEE,0XEE,0XEE,0XEE,0XEE,0XEE,0XEE,0XEA,0XAE,0XEF,0X8E,0X3E,0XEE,0XEF,0X80,0X00,
0X3F,0XFF,0XFF,0XFF,0XFF,0XFF,0XFF,0XFF,0X1F,0XFF,0XFF,0XFF,0XFF,0XFF,0XFF,0XFF,
0XFF,0XFF,0XFF,0X1F,0X1F,0XFF,0XFF,0X91,0X11,0X1F,0XFF,0XFF,0XFF,0XFF,0XFF,0XFF,
0XFF,0X3B,0XBB,0XBF,0XBB,0X99,0XBB,0XBB,0XBB,0XBB,0XBB,0XBA,0X0F,0X8B,0XBB,0XBB,
0X80,0X00,0X3F,0XFF,0XFF,0XFF,0XFF,0XFF,0XFF,0XFF,0X1F,0XFF,0XFD,0XFF,0XD7,0XFF,
0XF7,0XFF,0XFF,0XFF,0XFF,0X5F,0XC7,0XFF,0XFF,0XC4,0X44,0X7F,0XFF,0XFF,0XFF,0XFF,
0XFF,0XFF,0XFF,0X8E,0XEE,0XF8,0XEE,0XE3,0XEE,0XE0,0XEE,0XEE,0XEE,0XEE,0X0F,0XE0,
0XFE,0XFF,0X80,0X00,0X3F,0XFF,0XFF,0XFF,0XFF,0XFF,0XFF,0XFF,0X1F,0XFF,0XF0,0X7F,
0XF7,0XFF,0XC1,0XFF,0XFF,0XFF,0XFF,0X1F,0XF0,0X1F,0XFF,0X91,0X11,0X7F,0XFF,0XFF,
0XFF,0XFF,0XFF,0XFF,0XFF,0X8B,0XBB,0XA0,0X3B,0XBB,0XBB,0XC0,0XBB,0XBB,0XBB,0XBE,
0X3F,0XF8,0X0B,0XBB,0X80,0X00,0X3F,0XFF,0XFF,0XFF,0XFF,0XFF,0XFF,0XFF,0XCF,0XFF,
0XF0,0X7F,0XFF,0XFF,0XC5,0XFF,0XFF,0XFF,0XFE,0X3F,0XFF,0X45,0XFF,0XC4,0X44,0X7F,
0XFF,0XFF,0XFF,0XFF,0XFF,0XFF,0XFF,0X8E,0XEE,0XF8,0X2E,0XFF,0XEF,0XE0,0XEE,0XEE,
0XEE,0XEE,0X3F,0XFF,0X80,0XBF,0X80,0X00,0X7F,0XFF,0XFF,0XFF,0XFF,0XFF,0XFF,0XFF,
0XC7,0XFF,0XFC,0X7F,0XFF,0XFF,0XF1,0XFF,0XFF,0XFF,0XFC,0X7F,0XFF,0XD0,0X1F,0X11,
0X10,0X7F,0XFF,0XFF,0XFF,0XFF,0XFF,0XFF,0XFF,0X83,0XBB,0XB8,0XFB,0XBB,0XBB,0XBB,
0XBB,0XBB,0XBB,0XB8,0X3F,0XFF,0XF8,0X03,0X80,0X00,0XFF,0XFF,0XFF,0XFF,0XFF,0XFF,
0XFF,0XFF,0XC7,0XFF,0XFF,0XFF,0XFF,0XFF,0XFF,0XFF,0XFF,0XFF,0XFC,0X7F,0XFF,0XFF,
0X15,0X44,0X45,0XFF,0XFF,0XFF,0XFF,0XFF,0XFF,0XFF,0XFF,0XE3,0XEE,0XEF,0XEE,0XEE,
0XEE,0XFE,0XFE,0XEE,0XEE,0XE8,0XFF,0XFF,0XFF,0X80,0X00,0X00,0XFF,0XFF,0XFF,0XFF,
0XFF,0XFF,0XFF,0XFF,0XF1,0XFF,0XFF,0XFF,0XFF,0XFF,0XFF,0XFF,0XFF,0XFF,0XFD,0XFF,
0XFF,0XFF,0XF4,0X11,0X11,0XFF,0XFF,0XFF,0XFF,0XFF,0XFF,0XFF,0XFF,0XF1,0XBB,0XBB,
0XBB,0XBB,0XBB,0XBB,0XBB,0XBB,0XBB,0XB8,0XFF,0XFF,0XFF,0XFE,0X00,0X01,0XFF,0XFF,
0XFF,0XFF,0XFF,0XFF,0XFF,0XFF,0XF9,0XFF,0XFF,0XFF,0XFF,0XFF,0XFF,0XFF,0XFF,0XFF,
0XF0,0X5F,0XFF,0XFF,0XFF,0XF0,0X41,0XFF,0XFF,0XFF,0XFF,0XFF,0XFF,0XFF,0XFF,0XF8,
0XEF,0XEE,0XEE,0XEE,0XEE,0XFF,0XFE,0XEE,0XEE,0XFA,0X03,0XFF,0XFF,0XFF,0XFA,0X03,
0XFF,0XFF,0XFF,0XFF,0XFF,0XFF,0XFF,0XFF,0XFC,0X7F,0XFF,0XFF,0XFF,0XFF,0XFF,0XFF,
0XFF,0XFF,0XFF,0X41,0XFF,0XFF,0XFF,0XFF,0XFF,0XFF,0XFF,0XFF,0XFF,0XFF,0XFF,0XFF,
0XFF,0XFE,0X3B,0XBB,0XBB,0XBB,0XBB,0XBB,0XBB,0XFB,0XBB,0XBB,0XA0,0X3F,0XFF,0XFF,
0XFF,0XFF,0XFF,0XFF,0XFF,0XFF,0XFF,0XFF,0XFF,0XFF,0XFF,0X7F,0XFF,0XFF,0XFF,0XFF,
0XFF,0XFF,0XFF,0XFF,0XFF,0XF4,0X1F,0XFF,0XFF,0XFF,0XFF,0XFF,0XFF,0XFF,0XFF,0XFF,
0XFF,0XFF,0XFF,0XFE,0XFF,0XFF,0XFF,0XFE,0XFE,0XFE,0XFF,0X87,0XEE,0XEE,0XFE,0X03,
0XFF,0XFF,0XFF,0XFF,0XFF,0XFF,0XFF,0XFF,0XFF,0XFF,0XFF,0XFF,0XFC,0X7F,0XFF,0XFF,
0XFF,0XFF,0XFF,0XFF,0X57,0XFF,0XFF,0XFF,0X81,0XFF,0XFF,0XFF,0XFF,0XFF,0XFF,0XFF,
0XFF,0XFF,0XFF,0XFF,0XFF,0XF8,0XFB,0XBA,0XAA,0XBF,0XFB,0XBF,0XEA,0X83,0XBB,0XBB,
0XBB,0XA0,0X3F,0XFF,0XFF,0XFF,0XFF,0XFF,0XFF,0XFF,0XFF,0XFF,0XFF,0XFF,0XFC,0XFF,
0XF5,0X55,0X57,0XFF,0XFF,0X55,0X55,0XFF,0XFF,0XFF,0XF4,0X1F,0XFF,0XFF,0XFF,0XFF,
0XFF,0XFF,0XFF,0XFF,0XFF,0XFF,0XFF,0XF8,0XEF,0XE2,0X22,0X00,0X22,0XA0,0X02,0XA3,
0XEE,0XEE,0XEE,0XFE,0X07,0XFF,0XFF,0XFF,0XFF,0XFF,0XFF,0XFF,0XFF,0XFF,0XFF,0XFF,
0XFD,0XFF,0XF5,0X55,0X55,0X55,0X55,0X55,0X55,0XFF,0XFF,0XFF,0XFF,0X11,0XFF,0XFF,
0XFF,0XFF,0XFF,0XFF,0XFF,0XFF,0XFF,0XFF,0XFF,0XF8,0XFB,0XA0,0X88,0X88,0X88,0X88,
0X88,0X88,0X8F,0XBB,0XBB,0XBB,0X80,0XFF,0XFF,0XFF,0XFF,0XFF,0XFF,0XFF,0XFF,0XFF,
0XFF,0XFF,0XFD,0XFF,0XF5,0X55,0X55,0X55,0X55,0X55,0X54,0X47,0XFF,0XFF,0XFF,0XE4,
0X7F,0XFF,0XFF,0XFF,0XFF,0XFF,0XFF,0XFF,0XFF,0XFF,0XFF,0XF8,0XFE,0XFA,0X22,0XAA,
0XA2,0XAA,0XA0,0X22,0X22,0XFE,0XEF,0XEE,0XC0,0X3F,0XFF,0XFF,0XFF,0XFF,0XFF,0XFF,
0XFF,0XFF,0XFF,0XFF,0XF9,0XFF,0XF5,0X55,0X55,0X55,0X55,0X55,0X55,0X31,0X7F,0XFF,
0XFF,0X91,0X1F,0XFF,0XFF,0XFF,0XFF,0XFF,0XFF,0XFF,0XFF,0XFF,0XFF,0XF8,0XFB,0XA0,
0X88,0X00,0X00,0X80,0X08,0X88,0X38,0X0B,0XFB,0XBE,0X00,0X0F,0XFF,0XFF,0XFF,0XFF,
0XFF,0XFF,0XFF,0XFF,0XFF,0XFF,0XFC,0XFF,0XF5,0X55,0X55,0X55,0X55,0X55,0X55,0X7F,
0X05,0X7F,0XFC,0X44,0X4F,0XFF,0XFF,0XFF,0XFF,0XFF,0XFF,0XFF,0XFF,0XFF,0XFF,0XF8,
0XEE,0XE2,0X22,0XA2,0X22,0X22,0XAA,0X2A,0X3F,0X80,0X2A,0XF8,0X00,0X0F,0XFF,0XFF,
0XFF,0XFF,0XFF,0XFF,0XFF,0XFF,0XFF,0XFF,0XF8,0XFF,0XC7,0X55,0X55,0X55,0X55,0X55,
0X55,0X7F,0XF0,0X01,0X51,0X11,0X07,0XFF,0XFF,0XFF,0XFF,0XFF,0XFF,0XFF,0XFF,0XFF,
0XFF,0XF8,0XFB,0XC6,0X08,0X88,0X88,0X88,0X88,0X88,0X3F,0XFE,0X00,0X00,0X00,0X3F,
0XFF,0XFF,0XFF,0XFF,0XFF,0XFF,0XFF,0XFF,0XFF,0XFF,0XFC,0X7F,0XC7,0X55,0X55,0X55,
0X55,0X55,0X54,0X7F,0XFF,0XF4,0X00,0X05,0XFF,0XFF,0XFF,0XFF,0XFF,0XFF,0XFF,0XFF,
0XFF,0XFF,0XFF,0XF8,0XFE,0XC6,0X2A,0X2A,0X2A,0XAA,0X2A,0XA8,0XFF,0XFF,0XFE,0XA2,
0X2F,0XFF,0XFF,0XFF,0XFF,0XFF,0XFF,0XFF,0XFF,0XFF,0XFF,0XFF,0XFC,0X7F,0XC7,0X15,
0X55,0X55,0X55,0X55,0X51,0XFF,0XFF,0XFF,0XFF,0XFF,0XFF,0XFF,0XFF,0XFF,0XFF,0XFF,
0XFF,0XFF,0XFF,0XFF,0XFF,0XF8,0X3B,0X8F,0X88,0X88,0X88,0X88,0X88,0X81,0XFF,0XFF,
0XFF,0XFF,0XFF,0XFF,0XFF,0XFF,0XFF,0XFF,0XFF,0XFF,0XFF,0XFF,0XFF,0XFF,0XFC,0X7F,
0XC7,0XC5,0X55,0X55,0X55,0X55,0X57,0XFF,0XFF,0XFF,0XFF,0XFF,0XFF,0XFF,0XFF,0XFF,
0XFF,0XFF,0XFF,0XFF,0XFF,0XEF,0XFF,0XFC,0X2F,0X8F,0XE2,0XAA,0XAA,0XA2,0XAA,0XA7,
0XFF,0XFF,0XFF,0XFF,0XFF,0XFF,0XFF,0XFF,0XFF,0XFF,0XFF,0XFF,0XFF,0XFF,0XFF,0XFF,
0XFC,0X7F,0X9F,0XF1,0X55,0X55,0X55,0X55,0X5F,0XFF,0XFF,0XFF,0XFF,0XFF,0XFF,0XFF,
0XFF,0XFF,0XFF,0XFF,0XFF,0XFF,0XFF,0XBB,0XFF,0XFC,0X0F,0X8F,0XF8,0X08,0X88,0X88,
0X8A,0X3F,0XFF,0XFF,0XFF,0XFF,0XFF,0XFF,0XFF,0XFF,0XFF,0XFF,0XFF,0XFF,0XFF,0XFF,
0XFF,0XFF,0XFC,0X47,0X5F,0XFC,0X55,0X55,0X55,0X54,0X7F,0XFF,0XFF,0XFF,0XFF,0XFF,
0XFF,0XFF,0XFF,0XFF,0XFF,0XFF,0XFF,0XFF,0XFF,0XEF,0XEF,0XFE,0X02,0X0F,0XFE,0X02,
0XAA,0X2A,0XA0,0XFF,0XFF,0XFF,0XFF,0XFF,0XFF,0XFF,0XFF,0XFF,0XFF,0XFF,0XFF,0XFF,
0XFF,0XFF,0XFF,0XFF,0XFF,0X11,0X1F,0XFF,0XC1,0X55,0X55,0X51,0XFF,0XFF,0XFF,0XFF,
0XFF,0XFF,0XFF,0XFF,0XFF,0XFF,0XFF,0XFF,0XFF,0XFF,0XFB,0XBB,0XBB,0XFE,0X00,0X1F,
0XFF,0XE0,0X00,0X08,0X03,0XFF,0XFF,0XFF,0XFF,0XFF,0XFF,0XFF,0XFF,0XFF,0XFF,0XFF,
0XFF,0XFF,0XFF,0XFF,0XFF,0XFF,0XFF,0X44,0X1F,0XFF,0XFC,0X04,0X44,0X5F,0XFF,0XFF,
0XFF,0XFF,0XFF,0XFF,0XFF,0XFF,0XFF,0XFF,0XFF,0XFF,0XFF,0XFF,0XFE,0XEF,0XFF,0XFF,
0X00,0X3F,0XFF,0XFE,0X80,0X00,0X3F,0XFF,0XFF,0XFF,0XFF,0XFF,0XFF,0XFF,0XFF,0XFF,
0XFF,0XFF,0XFF,0XFF,0XFF,0XFF,0XFF,0XFF,0XFF,0X11,0X3F,0XFF,0XFF,0XFD,0X50,0XFF,
0XFF,0XFF,0XFF,0XFF,0XFF,0XFF,0XFF,0XFF,0XFF,0XFF,0XFF,0XFF,0XFF,0XFF,0XFF,0XBB,
0XBB,0XFF,0X80,0X3F,0XFF,0XFF,0XFF,0XF8,0XFF,0XFF,0XFF,0XFF,0XFF,0XFF,0XFF,0XFF,
0XFF,0XFF,0XFF,0XFF,0XFF,0XFF,0XFF,0XFF,0XFF,0XFF,0XFF,0XC4,0X7F,0XFF,0XFF,0XFF,
0XFF,0XFF,0XFF,0XFF,0XFF,0XFF,0XFF,0XFF,0XFF,0XFF,0XFF,0XFF,0XFF,0XFF,0XFF,0XFF,
0XFF,0XEE,0XEF,0XFF,0XC0,0X7F,0XFF,0XFF,0XFF,0XFF,0XFF,0XFF,0XFF,0XFF,0XFF,0XFF,
0XFF,0XFF,0XFF,0XFF,0XFF,0XFF,0XFF,0XFF,0XFF,0XFF,0XFF,0XFF,0XFF,0XC0,0XFF,0XFF,
0XFF,0XFF,0XFF,0XFF,0XFF,0XFF,0XFF,0XFF,0XFF,0XFF,0XFF,0XFF,0XFF,0XFF,0XFF,0XFF,
0XFF,0XFF,0XFF,0XBB,0XBF,0XFF,0XE0,0XFF,0XFF,0XFF,0XFF,0XFF,0XFF,0XFF,0XFF,0XFF,
0XFF,0XFF,0XFF,0XFF,0XFF,0XFF,0XFF,0XFF,0XFF,0XFF,0XFF,0XFF,0XFF,0XFF,0XFF,0XF1,
0XFF,0XFF,0XFF,0XFF,0XFF,0XFF,0XFF,0XFF,0XFF,0XFF,0XFF,0XFF,0XFF,0XFF,0XFF,0XFF,
0XFF,0XFF,0XFF,0XFF,0XFF,0XEF,0XEF,0XFF,0XFB,0XFF,0XFF,0XFF,0XFF,0XFF,0XFF,0XFF,
0XFF,0XFF,0XFF,0XFF,0XFF,0XFF,0XFF,0XFF,0XFF,0XFF,0XFF,0XFF,0XFF,0XFF,0XFF,0XFF,
0XFF,0XFF,0XFF,0XFF,0XFF,0XFF,0XFF,0XFF,0XFF,0XFF,0XFF,0XFF,0XFF,0XFF,0XFF,0XFF,
0XFF,0XFF,0XFF,0XFF,0XFF,0XFF,0XFF,0XFF,0XFF,0XFF,0XFF,0XFF,0XFF,0XFF,0XFF,0XFF,
0XFF,0XFF,0XFF,0XFF,0XFF,0XFF,0XFF,0XFF,0XFF,0XFF,0XFF,0XFF,0XFF,0XFF,0XFF,0XFF,
0XFF,0XFF,0XFF,0XFF,0XFF,0XFF,0XFF,0XFF,0XFF,0XFF,0XFF,0XFF,0XFF,0XFF,0XFF,0XFF,
0XFF,0XFF,0XFF,0XFF,0XFF,0XFF,0XFF,0XFF,0XFF,0XFF,0XFF,0XFF,0XFF,0XFF,0XFF,0XFF,
0XFF,0XFF,0XFF,0XFF,0XFF,0XFF,0XFF,0XFF,0XFF,0XFF,0XFF,0XFF,0XFF,0XFF,0XFF,0XFF,
0XFF,0XFF,0XFF,0XFF,0XFF,0XFF,0XFF,0XFF,0XFF,0XFF,0XFF,0XFF,0XFF,0XFF,0XFF,0XFF,
0XFF,0XFF,0XFF,0XFF,0XFF,0XFF,0XFF,0XFF,0XFF,0XFF,0XFF,0XFF,0XFF,0XFF,0XFF,0XFF,
0XFF,0XFF,0XFF,0XFF,0XFF,0XFF,0XFF,0XFF,0XFF,0XFF,0XFF,0XFF,0XFF,0XFF,0XFF,0XFF,
0XFF,0XFF,0XFF,0XFF,0XFF,0XFF,0XFF,0XFF,0XFF,0XFF,0XFF,0XFF,0XFF,0XFF,0XFF,0XFF,
0XFF,0XFF,0XFF,0XFF,0XFF,0XFF,0XFF,0XFF,0XFF,0XFF,0XFF,0XFF,0XFF,0XFF,0XFF,0XFF,
0XFF,0XFF,0XFF,0XFF,0XFF,0XFF,0XFF,0XFF,0XFF,0XFF,0XFF,0XFF,0XFF,0XFF,0XFF,0XFF,
0XFF,0XFF,0XFF,0XFF,0XFF,0XFF,0XFF,0XFF,0XFF,0XFF,0XFF,0XFF,0XFF,0XFF,0XFF,0XFF,
0XFF,0XFF,0XFF,0XFF,0XFF,0XFF,0XFF,0XFF,0XFF,0XFF,0XFF,0XFF,0XFF,0XFF,0XFF,0XFF,
0XFF,0XFF,0XFF,0XFF,0XFF,0XFF,0XFF,0XFF,0XFF,0XFF,0XFF,0XFF,0XFF,0XFF,0XFF,0XFF,
0XFF,0XFF,0XFF,0XFF,0XFF,0XFF,0XFF,0XFF,0XFF,0XFF,0XFF,0XFF,0XFF,0XFF,0XFF,0XFF,
0XFF,0XFF,0XFF,0XFF,0XFF,0XFF,0XFF,0XFF,0XFF,0XFF,0XFF,0XFF,0XFF,0XFF,0XFF,0XFF,
0XFF,0XFF,0XFF,0XFF,0XFF,0XFF,0XFF,0XFF,0XFF,0XFF,0XFF,0XFF,0XFF,0XFF,0XFF,0XFF,
0XFF,0XFF,0XFF,0XFF,0XFF,0XFF,0XFF,0XFF,0XFF,0XFF,0XFF,0XFF,0XFF,0XFF,0XFF,0XFF,
0XFF,0XFF,0XFF,0XFF,0XFF,0XFF,0XFF,0XFF,0XFF,0XFF,0XFF,0XFF,0XFF,0XFF,0XFF,0XFF,
0XFF,0XFF,0XFF,0XFF,0XFF,0XFF,0XFF,0XFF,0XFF,0XFF,0XFF,0XFF,0XFF,0XFF,0XFF,0XFF,
0XFF,0XFF,0XFF,0XFF,0XFF,0XFF,0XFF,0XFF,0XFF,0XFF,0XFF,0XFF,0XFF,0XFF,0XFF,0XFF,
0XFF,0XFF,0XFF,0XFF,0XFF,0XFF,0XFF,0XFF,0XFF,0XFF,0XFF,0XFF,0XFF,0XFF,0XFF,0XFF,
0XFF,0XFF,0XFF,0XFF,0XFF,0XFF,0XFF,0XFF,0XFF,0XFF,0XFF,0XFF,0XFF,0XFF,0XFF,0XFF,
0XFF,0XFF,0XFF,0XFF,0XFF,0XFF,0XFF,0XFF,0XFF,0XFF,0XFF,0XFF,0XFF,0XFF,0XFF,0XFF,
0XFF,0XFF,0XFF,0XFF,0XFF,0XFF,0XFF,0XFF,0XFF,0XFF,0XFF,0XFF,0XFF,0XFF,0XFF,0XFF,
0XFF,0XFF,0XFF,0XFF,0XFF,0XFF,0XFF,0XFF,0XFF,0XFF,0XFF,0XFF,0XFF,0XFF,0XFF,0XFF,
0XFF,0XFF,0XFF,0XFF,0XFF,0XFF,0XFF,0XFF,0XFF,0XFF,0XFF,0XFF,0XFF,0XFF,0XFF,0XFF,
0XFF,0XFF,0XFF,0XFF,0XFF,0XFF,0XFF,0XFF,0XFF,0XFF,0XFF,0XFF,0XFF,0XFF,0XFF,0XFF,
0XFF,0XFF,0XFF,0XFF,0XFF,0XFF,0XFF,0XFF,0XFF,0XFF,0XFF,0XFF,0XFF,0XFF,0XFF,0XFF,
0XFF,0XFF,0XFF,0XFF,0XFF,0XFF,0XFF,0XFF,0XFF,0XFF,0XFF,0XFF,0XFF,0XFF,0XFF,0XFF,
0XFF,0XFF,0XFF,0XFF,0XFF,0XFF,0XFF,0XFF,0XFF,0XFF,0XFF,0XFF,0XFF,0XFF,0XFF,0XFF,
0XFF,0XFF,0XFF,0XFF,0XFF,0XFF,0XFF,0XFF,0XFF,0XFF,0XFF,0XFF,0XFF,0XFF,0XFF,0XFF,
0XFF,0XFF,0XFF,0XFF,0XFF,0XFF,0XFF,0XFF,0XFF,0XFF,0XFF,0XFF,0XFF,0XFF,0XFF,0XFF,
0XFF,0XFF,0XFF,0XFF,0XFF,0XFF,0XFF,0XFF,0XFF,0XFF,0XFF,0XFF,0XFF,0XFF,0XFF,0XFF,
0XFF,0XFF,0XFF,0XFF,0XFF,0XFF,0XFF,0XFF,0XFF,0XFF,0XFF,0XFF,0XFF,0XFF,0XFF,0XFF,
0XFF,0XFF,0XFF,0XFF,0XFF,0XFF,0XFF,0XFF,0XFF,0XFF,0XFF,0XFF,0XFF,0XFF,0XFF,0XFF,
0XFF,0XFF,0XFF,0XFF,0XFF,0XFF,0XFF,0XFF,0XFF,0XFF,0XFF,0XFF,0XFF,0XFF,0XFF,0XFF,
0XFF,0XFF,0XFF,0XFF,0XFF,0XFF,0XFF,0XFF,0XFF,0XFF,0XFF,0XFF,0XFF,0XFF,0XFF,0XFF,
0XFF,0XFF,0XFF,0XFF,0XFF,0XFF,0XFF,0XFF,0XFF,0XFF,0XFF,0XFF,0XFF,0XFF,0XFF,0XFF,
0XFF,0XFF,0XFF,0XFF,0XFF,0XFF,0XFF,0XFF,0XFF,0XFF,0XFF,0XFF,0XFF,0XFF,0XFF,0XFF,
0XFF,0XFF,0XFF,0XFF,0XFF,0XFF,0XFF,0XFF,0XFF,0XFF,0XFF,0XFF,0XFF,0XFF,0XFF,0XFF,
0XFF,0XFF,0XFF,0XFF,0XFF,0XFF,0XFF,0XFF,0XFF,0XFF,0XFF,0XFF,0XFF,0XFF,0XFF,0XFF,
0XFF,0XFF,0XFF,0XFF,0XFF,0XFF,0XFF,0XFF,0XFF,0XFF,0XFF,0XFF,0XFF,0XFF,0XFF,0XFF,
0XFF,0XFF,0XFF,0XFF,0XFF,0XFF,0XFF,0XFF,0XFF,0XFF,0XFF,0XFF,0XFF,0XFF,0XFF,0XFF,
0XFF,0XFF,0XFF,0XFF,0XFF,0XFF,0XFF,0XFF,0XFF,0XFF,0XFF,0XFF,0XFF,0XFF,0XFF,0XFF,
0XFF,0XFF,0XFF,0XFF,0XFF,0XFF,0XFF,0XFF,0XFF,0XFF,0XFF,0XFF,0XFF,0XFF,0XFF,0XFF,
0XFF,0XFF,0XFF,0XFF,0XFF,0XFF,0XFF,0XFF,0XFF,0XFF,0XFF,0XFF,0XFF,0XFF,0XFF,0XFF,
0XFF,0XFF,0XFF,0XFF,0XFF,0XFF,0XFF,0XFF,0XFF,0XFF,0XFF,0XFF,0XFF,0XFF,0XFF,0XFF,
0XFF,0XFF,0XFF,0XFF,0XFF,0XFF,0XFF,0XFF,0XFF,0XFF,0XFF,0XFF,0XFF,0XFF,0XFF,0XFF,
0XFF,0XFF,0XFF,0XFF,0XFF,0XFF,0XFF,0XFF,0XFF,0XFF,0XFF,0XFF,0XFF,0XFF,0XFF,0XFF,
0XFF,0XFF,0XFF,0XFF,0XFF,0XFF,0XFF,0XFF,0XFF,0XFF,0XFF,0XFF,0XFF,0XFF,0XFF,0XFF,
0XFF,0XFF,0XFF,0XFF,0XFF,0XFF,0XFF,0XFF,0XFF,0XFF,0XFF,0XFF,0XFF,0XFF,0XFF,0XFF,
0XFF,0XFF,0XFF,0XFF,0XFF,0XFF,0XFF,0XFF,0XFF,0XFF,0XFF,0XFF,0XFF,0XFF,0XFF,0XFF,
0XFF,0XFF,0XFF,0XFF,0XFF,0XFF,0XFF,0XFF,0XFF,0XFF,0XFF,0XFF,0XFF,0XFF,0XFF,0XFF,
0XFF,0XFF,0XFF,0XFF,0XFF,0XFF,0XFF,0XFF,0XFF,0XFF,0XFF,0XFF,0XFF,0XFF,0XFF,0XFF,
0XFF,0XFF,0XFF,0XFF,0XFF,0XFF,0XFF,0XFF,0XFF,0XFF,0XFF,0XFF,0XFF,0XFF,0XFF,0XFF,
0XFF,0XFF,0XFF,0XFF,0XFF,0XFF,0XFF,0XFF,0XFF,0XFF,0XFF,0XFF,0XFF,0XFF,0XFF,0XFF,
0XFF,0XFF,0XFF,0XFF,0XFF,0XFF,0XFF,0XFF,0XFF,0XFF,0XFF,0XFF,0XFF,0XFF,0XFF,0XFF,
0XFF,0XFF,0XFF,0XFF,0XFF,0XFF,0XFF,0XFF,0XFF,0XFF,0XFF,0XFF,0XFF,0XFF,0XFF,0XFF,
0XFF,0XFF,0XFF,0XFF,0XFF,0XFF,0XFF,0XFF,0XFF,0XFF,0XFF,0XFF,0XFF,0XFF,0XFF,0XFF,
0XFF,0XFF,0XFF,0XFF,0XFF,0XFF,0XFF,0XFF,0XFF,0XFF,0XFF,0XFF,0XFF,0XFF,0XFF,0XFF,
0XFF,0XFF,0XFF,0XFF,0XFF,0XFF,0XFF,0XFF,0XFF,0XFF,0XFF,0XFF,0XFF,0XFF,0XFF,0XFF,
0XFF,0XFF,0XFF,0XFF,0XFF,0XFF,0XFF,0XFF,0XFF,0XFF,0XFF,0XFF,0XFF,0XFF,0XFF,0XFF,
0XFF,0XFF,0XFF,0XFF,0XFF,0XFF,0XFF,0XFF,0XFF,0XFF,0XFF,0XFF,0XFF,0XFF,0XFF,0XFF,
0XFF,0XFF,0XFF,0XFF,0XFF,0XFF,0XFF,0XFF,0XFF,0XFF,0XFF,0XFF,0XFF,0XFF,0XFF,0XFF,
0XFF,0XFF,0XFF,0XFF,0XFF,0XFF,0XFF,0XFF,0XFF,0XFF,0XFF,0XFF,0XFF,0XFF,0XFF,0XFF,
0XFF,0XFF,0XFF,0XFF,0XFF,0XFF,0XFF,0XFF,0XFF,0XFF,0XFF,0XFF,0XFF,0XFF,0XFF,0XFF,
0XFF,0XFF,0XFF,0XFF,0XFF,0XFF,0XFF,0XFF,0XFF,0XFF,0XFF,0XFF,0XFF,0XFF,0XFF,0XFF,
0XFF,0XFF,0XFF,0XFF,0XFF,0XFF,0XFF,0XFF,0XFF,0XFF,0XFF,0XFF,0XFF,0XFF,0XFF,0XFF,
0XFF,0XFF,0XFF,0XFF,0XFF,0XFF,0XFF,0XFF,0XFF,0XFF,0XFF,0XFF,0XFF,0XFF,0XFF,0XFF,
0XFF,0XFF,0XFF,0XFF,0XFF,0XFF,0XFF,0XFF,
};

/* USER CODE END PV */

void SystemClock_Config(void);

int main(void)
{

  /* MCU Configuration--------------------------------------------------------*/

  /* Reset of all peripherals, Initializes the Flash interface and the Systick. */
  HAL_Init();

  /* Configure the system clock */
  SystemClock_Config();

  /* Initialize all configured peripherals */
  MX_GPIO_Init();
  MX_USART2_UART_Init();
  MX_FATFS_Init();
  MX_SPI2_Init();
  MX_SPI1_Init();
  MX_TIM3_Init();
  /* USER CODE BEGIN 2 */
  SpiInit(&hspi1);

  printf("Welcome to X-NUCLEO-NFC05A1\r\n");

  //rfalAnalogConfigInitialize();
  /* USER CODE END 2 */
  if (!demoIni())
  {
    /*
    * in case the rfal initalization failed signal it by flashing all LED
    * and stoping all operations
    */
    printf("Initialization failed..\r\n");
    while (1)
    {
      platformLedToogle(PLATFORM_LED_V_PORT, PLATFORM_LED_V_PIN);
      platformDelay(100);
    }
  }
  else
  {
    printf("Initialization succeeded..\r\n");
    for (int i = 0; i < 6; i++)
    {
      platformLedToogle(PLATFORM_LED_V_PORT, PLATFORM_LED_V_PIN);
      platformDelay(200);
    }
    platformLedOff(PLATFORM_LED_V_PORT, PLATFORM_LED_V_PIN);
  }
  /* Infinite loop */
  while (1)
  {
		if(HAL_GPIO_ReadPin(KEY_DOWN_GPIO_Port, KEY_DOWN_Pin) == GPIO_PIN_RESET)
		{
		  demoCycle();
		}

		if(HAL_GPIO_ReadPin(KEY_UP_GPIO_Port, KEY_UP_Pin) == GPIO_PIN_RESET)
		{
		  nfcBufInit();//初始化三维数组
		}
		if(HAL_GPIO_ReadPin(KEY_BACK_GPIO_Port, KEY_BACK_Pin) == GPIO_PIN_RESET)
		{
		  nfcBuf2Init();//初始化三维数组
		}

  }
}

void SystemClock_Config(void)
{
  RCC_OscInitTypeDef RCC_OscInitStruct = {0};
  RCC_ClkInitTypeDef RCC_ClkInitStruct = {0};

  /** Initializes the RCC Oscillators according to the specified parameters
  * in the RCC_OscInitTypeDef structure.
  */
  RCC_OscInitStruct.OscillatorType = RCC_OSCILLATORTYPE_HSE;
  RCC_OscInitStruct.HSEState = RCC_HSE_ON;
  RCC_OscInitStruct.HSEPredivValue = RCC_HSE_PREDIV_DIV1;
  RCC_OscInitStruct.HSIState = RCC_HSI_ON;
  RCC_OscInitStruct.PLL.PLLState = RCC_PLL_ON;
  RCC_OscInitStruct.PLL.PLLSource = RCC_PLLSOURCE_HSE;
  RCC_OscInitStruct.PLL.PLLMUL = RCC_PLL_MUL9;
  if (HAL_RCC_OscConfig(&RCC_OscInitStruct) != HAL_OK)
  {
    Error_Handler();
  }
  /** Initializes the CPU, AHB and APB buses clocks
  */
  RCC_ClkInitStruct.ClockType = RCC_CLOCKTYPE_HCLK | RCC_CLOCKTYPE_SYSCLK | RCC_CLOCKTYPE_PCLK1 | RCC_CLOCKTYPE_PCLK2;
  RCC_ClkInitStruct.SYSCLKSource = RCC_SYSCLKSOURCE_PLLCLK;
  RCC_ClkInitStruct.AHBCLKDivider = RCC_SYSCLK_DIV1;
  RCC_ClkInitStruct.APB1CLKDivider = RCC_HCLK_DIV2;
  RCC_ClkInitStruct.APB2CLKDivider = RCC_HCLK_DIV1;

  if (HAL_RCC_ClockConfig(&RCC_ClkInitStruct, FLASH_LATENCY_2) != HAL_OK)
  {
    Error_Handler();
  }
}

void Error_Handler(void)
{
  __disable_irq();
  while (1)
  {
  }
}

/************************ (C) COPYRIGHT STMicroelectronics *****END OF FILE****/
